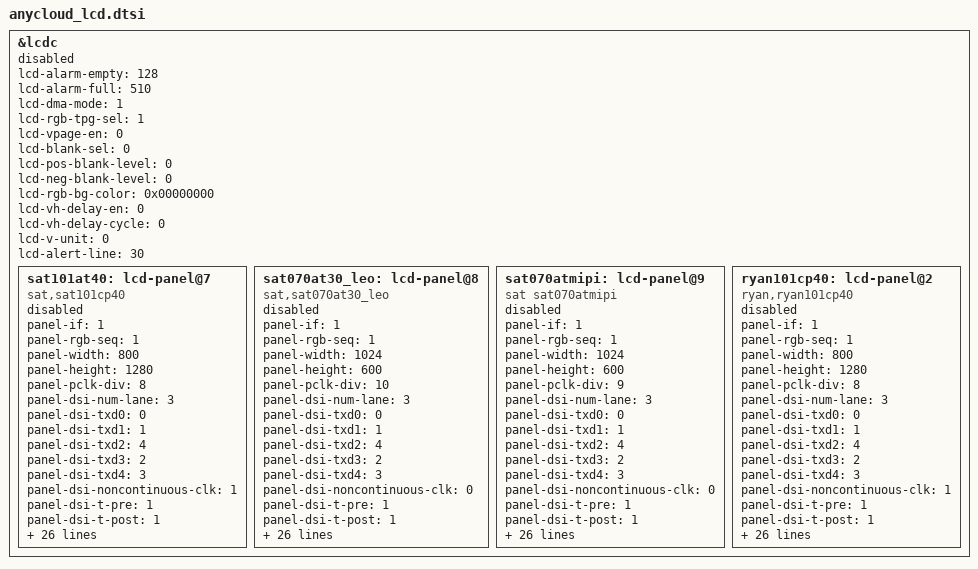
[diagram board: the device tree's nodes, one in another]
/*
 * Anycloud LCD panel dts
 *
 * Copyright (C) 2018 Anyka(Guangzhou) Microelectronics Technology Co., Ltd.
 *
 * Author: Feilong Dong <dong_feilong@anyka.com>
 *
 * This program is free software; you can redistribute it and/or modify
 * it under the terms of the GNU General Public License as published by
 * the Free Software Foundation; either version 2 of the License, or
 * (at your option) any later version.
 *
 * This program is distributed in the hope that it will be useful,
 * but WITHOUT ANY WARRANTY; without even the implied warranty of
 * MERCHANTABILITY or FITNESS FOR A PARTICULAR PURPOSE.  See the
 * GNU General Public License for more details.
 */

&lcdc {
    lcd-alarm-empty = <128>;
    lcd-alarm-full = <510>;
    lcd-dma-mode = <1>;
    //lcd-dummy-seq = <0>; //for 8bit rgb panel set
    //lcd-rgb-seq-sel = <0>;
    //lcd-rgb-odd-seq = <0>;
    //lcd-rgb-even-seq = <0>;
    lcd-rgb-tpg-sel = <1>;
    lcd-vpage-en = <0>; //don't support vpage function in driver
    lcd-blank-sel = <0>;
    lcd-pos-blank-level = <0>;
    lcd-neg-blank-level = <0>;
    lcd-rgb-bg-color = <0x00000000>;
    lcd-vh-delay-en = <0>;
    lcd-vh-delay-cycle = <0>;
    lcd-v-unit = <0>;
    lcd-alert-line = <30>;
    status = "disable";
    
    // sat070cp50: lcd-panel@0 { //for RGB panel setting
    //     compatible = "sat,sat070cp50";
    //     panel-if = <0>; //0 for RGB, 1 for MIPI, 2 for MPU
    //     panel-rgb-seq = <1>; //0 for BGR, 1 for RGB
    //     panel-width = <1024>;
    //     panel-height = <600>;
    //     panel-pclk-div = <10>; //pixel clock = Peri_pll/(pclk_div+1)
    //     panel-thpw = <60>;
    //     panel-thb = <100>;
    //     panel-thf = <120>;
    //     panel-tvpw = <2>;
    //     panel-tvb = <21>;
    //     panel-tvf = <12>;
    //     panel-pclk-pol = <0>; //0:pos, 1:neg
    //     panel-hsync-pol = <1>;
    //     panel-vsync-pol = <1>;
    //     panel-vogate-pol = <0>;
    //     panel-bus-width = <3>; //0:8bits,1:16bits,2:18bits,3:24bits
    //     panel-sync-mode = <1>; 

    //     status = "disable";
    // };

    // adt07016BR50: lcd-panel@1 { //for AJB RGB panel setting
    //     compatible = "sat,sat070cp50";
    //     panel-if = <0>; //0 for RGB, 1 for MIPI, 2 for MPU
    //     panel-rgb-seq = <1>; //0 for BGR, 1 for RGB
    //     panel-width = <1024>;
    //     panel-height = <600>;
    //     panel-pclk-div = <10>; //pixel clock = Peri_pll/(pclk_div+1)
    //     panel-thpw = <60>;
    //     panel-thb = <100>;
    //     panel-thf = <120>;
    //     panel-tvpw = <2>;
    //     panel-tvb = <21>;
    //     panel-tvf = <12>;
    //     panel-pclk-pol = <0>; //0:pos, 1:neg
    //     panel-hsync-pol = <1>;
    //     panel-vsync-pol = <1>;
    //     panel-vogate-pol = <0>;
    //     panel-bus-width = <3>; //0:8bits,1:16bits,2:18bits,3:24bits
    //     panel-sync-mode = <1>; 

    //     status = "disable";
    // };
/*

    sat101at40: lcd-panel@2 { //for JD9364 MIPI panel setting
        compatible = "sat,sat101at40";
        panel-if = <1>; //0 for RGB, 1 for MIPI, 2 for MPU
        panel-rgb-seq = <1>; //0 for BGR, 1 for RGB
        panel-width = <800>;
        panel-height = <1280>;
        panel-pclk-div = <8>; //pixel clock = Peri_pll/(pclk_div+1)
        panel-dsi-num-lane = <3>; //0-3: 1lane-4lane
        //0-3: data0-data3, 4: clk
        panel-dsi-txd0 = <2>;
        panel-dsi-txd1 = <1>;
        panel-dsi-txd2 = <4>;
        panel-dsi-txd3 = <0>;
        panel-dsi-txd4 = <3>;
        panel-dsi-noncontinuous-clk = <0>; //0:continuous,1:noncontinuous
        panel-dsi-t-pre = <1>; //t-pre, >=1
        panel-dsi-t-post = <1>; //t-post=tlpx+t-prepare+t-zero+t-pre, >=1
        panel-dsi-tx-gap = <1>; //ths-exit
        panel-dsi-autoinsert-eotp = <0>; //0:not insert,1:auto-insert
        panel-dsi-htx-to-count = <0xFFFFFF>; //high speed TX timeout count
        panel-dsi-lrx-to-count = <0xFFFFFF>; //Low power RX timeout count
        panel-dsi-bta-to-count = <0xFFFFFF>; //Bus turn around timeout count
        panel-dsi-t-wakeup = <0xc8>; //DPHY T-wakeup time
        panel-dsi-pix-fifo-send-level = <512>; //buffer send level <= 512
        //0-2:16-bit config 1-3; 3-4:18-bit config 1-2; 5:24-bit
        panel-dsi-if-color-coding = <0x05>;
        //0:16-bit;1:18-bit;2:18-bit loosely packed;3:24-bit
        panel-dsi-pix-format = <0x03>;
        panel-dsi-vsync-pol = <0>; //0:active low; 1:active high
        panel-dsi-hsync-pol = <0>; //0:active low; 1:active high
        //0:Non-burst mode with sync pulses;
        //1:Noe-burst mode with sync events;
        //2:Burst mode; 3:reserved
        panel-dsi-video-mode = <2>;
        panel-dsi-hfp = <32>; //H front porch blanking packet payload size in bytes
        panel-dsi-hbp = <8>; //H back porch blanking packet payload size in bytes
        panel-dsi-hsa = <8>; //H sync width blanking packet payload size in bytes
        panel-dsi-mult-pkts-en = <0>; //0: single packet;1: two packets
        panel-dsi-vbp = <8>; //V back porch lines
        panel-dsi-vfp = <30>; //V front porch lines
        panel-dsi-vsa = <4>;
        //0:blanking packets send during BLLP;1:LP mode used for BLLP
        panel-dsi-bllp-mode = <1>;
        panel-dsi-use-null-pkt-bllp = <0>; //0:blanking packet; 1:Null packet
        panel-dsi-vc = <0x00>; //Virtual channel
        panel-dsi-cmd-type = <0x0>; //0:send in LP mode, 1:send in HS mode
        panel-dsi-clk = <600>;
        //add special config list here
        panel-init-list = <0x00 0x23 0xE0 0x00 0xFFF
                            0x00 0x23 0xE1 0x93 0xFFF
                            0x00 0x23 0xE2 0x65 0xFFF
                            0x00 0x23 0xE3 0xF8 0xFFF
                            0x00 0x23 0x70 0x10 0xFFF
                            0x00 0x23 0x71 0x13 0xFFF
                            0x00 0x23 0x72 0x06 0xFFF
                            0x00 0x23 0x80 0x03 0xFFF
                            0x00 0x23 0xE0 0x04 0xFFF
                            0x00 0x23 0x2D 0x03 0xFFF
                            0x00 0x23 0xE0 0x01 0xFFF
                            0x00 0x23 0x00 0x00 0xFFF
                            0x00 0x23 0x01 0xB3 0xFFF
                            0x00 0x23 0x17 0x00 0xFFF
                            0x00 0x23 0x18 0xD8 0xFFF
                            0x00 0x23 0x19 0x05 0xFFF
                            0x00 0x23 0x1A 0x00 0xFFF
                            0x00 0x23 0x1B 0xD8 0xFFF
                            0x00 0x23 0x1C 0x05 0xFFF
                            0x00 0x23 0x1F 0x7E 0xFFF
                            0x00 0x23 0x20 0x28 0xFFF
                            0x00 0x23 0x21 0x28 0xFFF
                            0x00 0x23 0x22 0x0E 0xFFF
                            0x00 0x23 0x24 0xF8 0xFFF
                            0x00 0x23 0x26 0xF3 0xFFF
                            0x00 0x23 0x27 0x44 0xFFF
                            0x00 0x23 0x37 0x59 0xFFF
                            0x00 0x23 0x38 0x05 0xFFF
                            0x00 0x23 0x39 0x0C 0xFFF
                            0x00 0x23 0x3A 0x18 0xFFF
                            0x00 0x23 0x3C 0x78 0xFFF
                            0x00 0x23 0x3E 0x78 0xFFF
                            0x00 0x23 0x40 0x06 0xFFF
                            0x00 0x23 0x41 0xA0 0xFFF
                            0x00 0x23 0x55 0x01 0xFFF
                            0x00 0x23 0x56 0x01 0xFFF
                            0x00 0x23 0x57 0xA8 0xFFF
                            0x00 0x23 0x58 0x0A 0xFFF
                            0x00 0x23 0x59 0x2A 0xFFF
                            0x00 0x23 0x5A 0x3C 0xFFF
                            0x00 0x23 0x5B 0x14 0xFFF
                            0x00 0x23 0x5D 0x70 0xFFF
                            0x00 0x23 0x5E 0x53 0xFFF
                            0x00 0x23 0x5F 0x42 0xFFF
                            0x00 0x23 0x60 0x35 0xFFF
                            0x00 0x23 0x61 0x32 0xFFF
                            0x00 0x23 0x62 0x23 0xFFF
                            0x00 0x23 0x63 0x28 0xFFF
                            0x00 0x23 0x64 0x13 0xFFF
                            0x00 0x23 0x65 0x2D 0xFFF
                            0x00 0x23 0x66 0x2D 0xFFF
                            0x00 0x23 0x67 0x2D 0xFFF
                            0x00 0x23 0x68 0x4B 0xFFF
                            0x00 0x23 0x69 0x39 0xFFF
                            0x00 0x23 0x6A 0x40 0xFFF
                            0x00 0x23 0x6B 0x2F 0xFFF
                            0x00 0x23 0x6C 0x26 0xFFF
                            0x00 0x23 0x6D 0x1E 0xFFF
                            0x00 0x23 0x6E 0x07 0xFFF
                            0x00 0x23 0x6F 0x02 0xFFF
                            0x00 0x23 0x70 0x70 0xFFF
                            0x00 0x23 0x71 0x53 0xFFF
                            0x00 0x23 0x72 0x42 0xFFF
                            0x00 0x23 0x73 0x35 0xFFF
                            0x00 0x23 0x74 0x32 0xFFF
                            0x00 0x23 0x75 0x23 0xFFF
                            0x00 0x23 0x76 0x28 0xFFF
                            0x00 0x23 0x77 0x13 0xFFF
                            0x00 0x23 0x78 0x2D 0xFFF
                            0x00 0x23 0x79 0x2D 0xFFF
                            0x00 0x23 0x7A 0x2D 0xFFF
                            0x00 0x23 0x7B 0x4B 0xFFF
                            0x00 0x23 0x7C 0x39 0xFFF
                            0x00 0x23 0x7D 0x40 0xFFF
                            0x00 0x23 0x7E 0x2F 0xFFF
                            0x00 0x23 0x7F 0x26 0xFFF
                            0x00 0x23 0x80 0x1E 0xFFF
                            0x00 0x23 0x81 0x07 0xFFF
                            0x00 0x23 0x82 0x02 0xFFF
                            0x00 0x23 0xE0 0x02 0xFFF
                            0x00 0x23 0x00 0x53 0xFFF
                            0x00 0x23 0x01 0x5F 0xFFF
                            0x00 0x23 0x02 0x5F 0xFFF
                            0x00 0x23 0x03 0x5F 0xFFF
                            0x00 0x23 0x04 0x5F 0xFFF
                            0x00 0x23 0x05 0x51 0xFFF
                            0x00 0x23 0x06 0x58 0xFFF
                            0x00 0x23 0x07 0x57 0xFFF
                            0x00 0x23 0x08 0x4F 0xFFF
                            0x00 0x23 0x09 0x5F 0xFFF
                            0x00 0x23 0x0A 0x4D 0xFFF
                            0x00 0x23 0x0B 0x4B 0xFFF
                            0x00 0x23 0x0C 0x5F 0xFFF
                            0x00 0x23 0x0D 0x49 0xFFF
                            0x00 0x23 0x0E 0x47 0xFFF
                            0x00 0x23 0x0F 0x45 0xFFF
                            0x00 0x23 0x10 0x41 0xFFF
                            0x00 0x23 0x11 0x5F 0xFFF
                            0x00 0x23 0x12 0x5F 0xFFF
                            0x00 0x23 0x13 0x5F 0xFFF
                            0x00 0x23 0x14 0x5F 0xFFF
                            0x00 0x23 0x15 0x5F 0xFFF
                            0x00 0x23 0x16 0x52 0xFFF
                            0x00 0x23 0x17 0x5F 0xFFF
                            0x00 0x23 0x18 0x5F 0xFFF
                            0x00 0x23 0x19 0x5F 0xFFF
                            0x00 0x23 0x1A 0x5F 0xFFF
                            0x00 0x23 0x1B 0x50 0xFFF
                            0x00 0x23 0x1C 0x58 0xFFF
                            0x00 0x23 0x1D 0x57 0xFFF
                            0x00 0x23 0x1E 0x4E 0xFFF
                            0x00 0x23 0x1F 0x5F 0xFFF
                            0x00 0x23 0x20 0x4C 0xFFF
                            0x00 0x23 0x21 0x4A 0xFFF
                            0x00 0x23 0x22 0x5F 0xFFF
                            0x00 0x23 0x23 0x48 0xFFF
                            0x00 0x23 0x24 0x46 0xFFF
                            0x00 0x23 0x25 0x44 0xFFF
                            0x00 0x23 0x26 0x40 0xFFF
                            0x00 0x23 0x27 0x5F 0xFFF
                            0x00 0x23 0x28 0x5F 0xFFF
                            0x00 0x23 0x29 0x5F 0xFFF
                            0x00 0x23 0x2A 0x5F 0xFFF
                            0x00 0x23 0x2B 0x5F 0xFFF
                            0x00 0x23 0x2C 0x52 0xFFF
                            0x00 0x23 0x2D 0x5F 0xFFF
                            0x00 0x23 0x2E 0x5F 0xFFF
                            0x00 0x23 0x2F 0x5F 0xFFF
                            0x00 0x23 0x30 0x5F 0xFFF
                            0x00 0x23 0x31 0x40 0xFFF
                            0x00 0x23 0x32 0x58 0xFFF
                            0x00 0x23 0x33 0x57 0xFFF
                            0x00 0x23 0x34 0x44 0xFFF
                            0x00 0x23 0x35 0x5F 0xFFF
                            0x00 0x23 0x36 0x46 0xFFF
                            0x00 0x23 0x37 0x48 0xFFF
                            0x00 0x23 0x38 0x5F 0xFFF
                            0x00 0x23 0x39 0x4A 0xFFF
                            0x00 0x23 0x3A 0x4C 0xFFF
                            0x00 0x23 0x3B 0x4E 0xFFF
                            0x00 0x23 0x3C 0x50 0xFFF
                            0x00 0x23 0x3D 0x5F 0xFFF
                            0x00 0x23 0x3E 0x5F 0xFFF
                            0x00 0x23 0x3F 0x5F 0xFFF
                            0x00 0x23 0x40 0x5F 0xFFF
                            0x00 0x23 0x41 0x5F 0xFFF
                            0x00 0x23 0x42 0x53 0xFFF
                            0x00 0x23 0x43 0x5F 0xFFF
                            0x00 0x23 0x44 0x5F 0xFFF
                            0x00 0x23 0x45 0x5F 0xFFF
                            0x00 0x23 0x46 0x5F 0xFFF
                            0x00 0x23 0x47 0x41 0xFFF
                            0x00 0x23 0x48 0x58 0xFFF
                            0x00 0x23 0x49 0x57 0xFFF
                            0x00 0x23 0x4A 0x45 0xFFF
                            0x00 0x23 0x4B 0x5F 0xFFF
                            0x00 0x23 0x4C 0x47 0xFFF
                            0x00 0x23 0x4D 0x49 0xFFF
                            0x00 0x23 0x4E 0x5F 0xFFF
                            0x00 0x23 0x4F 0x4B 0xFFF
                            0x00 0x23 0x50 0x4D 0xFFF
                            0x00 0x23 0x51 0x4F 0xFFF
                            0x00 0x23 0x52 0x51 0xFFF
                            0x00 0x23 0x53 0x5F 0xFFF
                            0x00 0x23 0x54 0x5F 0xFFF
                            0x00 0x23 0x55 0x5F 0xFFF
                            0x00 0x23 0x56 0x5F 0xFFF
                            0x00 0x23 0x57 0x5F 0xFFF
                            0x00 0x23 0x58 0x10 0xFFF
                            0x00 0x23 0x59 0x00 0xFFF
                            0x00 0x23 0x5A 0x00 0xFFF
                            0x00 0x23 0x5B 0x10 0xFFF
                            0x00 0x23 0x5C 0x05 0xFFF
                            0x00 0x23 0x5D 0x30 0xFFF
                            0x00 0x23 0x5E 0x00 0xFFF
                            0x00 0x23 0x5F 0x00 0xFFF
                            0x00 0x23 0x60 0x30 0xFFF
                            0x00 0x23 0x61 0x02 0xFFF
                            0x00 0x23 0x62 0x00 0xFFF
                            0x00 0x23 0x63 0x03 0xFFF
                            0x00 0x23 0x64 0x7B 0xFFF
                            0x00 0x23 0x65 0x75 0xFFF
                            0x00 0x23 0x66 0x0B 0xFFF
                            0x00 0x23 0x67 0xB3 0xFFF
                            0x00 0x23 0x68 0x07 0xFFF
                            0x00 0x23 0x69 0x06 0xFFF
                            0x00 0x23 0x6A 0x7B 0xFFF
                            0x00 0x23 0x6B 0x04 0xFFF
                            0x00 0x23 0x6C 0x00 0xFFF
                            0x00 0x23 0x6D 0x04 0xFFF
                            0x00 0x23 0x6E 0x04 0xFFF
                            0x00 0x23 0x6F 0x88 0xFFF
                            0x00 0x23 0x70 0x00 0xFFF
                            0x00 0x23 0x71 0x00 0xFFF
                            0x00 0x23 0x72 0x06 0xFFF
                            0x00 0x23 0x73 0x7B 0xFFF
                            0x00 0x23 0x74 0x00 0xFFF
                            0x00 0x23 0x75 0x80 0xFFF
                            0x00 0x23 0x76 0x00 0xFFF
                            0x00 0x23 0x77 0x0D 0xFFF
                            0x00 0x23 0x78 0x2A 0xFFF
                            0x00 0x23 0x79 0x00 0xFFF
                            0x00 0x23 0x7A 0x00 0xFFF
                            0x00 0x23 0x7B 0x00 0xFFF
                            0x00 0x23 0x7C 0x00 0xFFF
                            0x00 0x23 0x7D 0x03 0xFFF
                            0x00 0x23 0x7E 0x7B 0xFFF
                            0x00 0x23 0xE0 0x00 0xFFF
                            0x78 0x13 0x11 0x00 0xFFF
                            0x05 0x13 0x29 0x00 0xFFF
                            0x78 0x23 0x35 0x00 0xFFF>;

        status = "disable";
    };
*/
    // ili9342c: lcd-panel@3 {
    //     compatible = "mpu,ili9342c";
    //     panel-if = <2>;//0 for RGB, 1 for MIPI, 2 for MPU
    //     panel-width = <320>;
    //     panel-height = <240>;
    //     panel-pclk-div = <1>; //default pixel clock = Peri_pll(600M)/(pclk_div+1)=60M
    //     panel-data-width = <0>; //0:8bits,1:16bits,2:18bits,3:9bits
    //     panel-color-mode = <1>; //0:4K 1:64K/256K
    //     panel-rs-polarity = <1>; //0:negative(0 means data while 1 means command)
    //                             //1:positive(0 means command while 1 means data)
    //     panel-wr-cycle = <16>; // write timing setting, wr-cycle >= 4*(wr-low) (8/9bits mode)
    //     panel-wr-low = <4>; // write timing setting,wr_cycle_len/2 - wr_low_len >= 2 (8/9bits mode)

    //     /* 0 for portrait, 1 for landscape*/
    //     panel-direction = <0>; 

    // panel-init-list = <0xC8 0xFF 0x93 0x42 0xFFF
    //                          0x36 0xC8 0xFFF
    //                          0x3A 0x55 0xFFF
    //                          0xC0 0x13 0x0E 0xFFF
    //                          0xC1 0x02 0xFFF
    //                          0xC5 0xD5 0xFFF
    //                          0xB1 0x00 0x1B 0xFFF
    //                          0xB4 0x02 0xFFF
    //                          0xE0 0x00 0x07 0x0C 0x06
    //                          0x15 0x09 0x3A 0x36 0x48
    //                          0x02 0x0B 0x0A 0x15 0x16
    //                          0x0F 0xFFF
    //                          0xE1 0x00 0x25 0x26 0x02
    //                          0x0E 0x03 0x3D 0x13 0x4E
    //                          0x03 0x0E 0x0B 0x34 0x37
    //                          0x0F 0xFFF
    //                          0x11 0xFFF
    //                          0x29 0xFFF>;
    //     status = "disable";
    // };
    

    // ili9488: lcd-panel@4 {
	// 	compatible = "mpu,ili9488";
	// 	panel-if = <2>;//0 for RGB, 1 for MIPI, 2 for MPU
	// 	panel-width = <320>;
	// 	panel-height = <480>;
	// 	panel-pclk-div = <9>; //default pixel clock = Peri_pll(600M)/(pclk_div+1)=60M
	// 	panel-data-width = <1>; //0:8bits,1:16bits,2:18bits,3:9bits
	// 	panel-color-mode = <1>; //0:4K 1:64K/256K
	// 	panel-rs-polarity = <1>; //0:negative(0 means data while 1 means command)
	// 							//1:positive(0 means command while 1 means data)
	// 	panel-wr-cycle = <8>; // write timing setting, wr-cycle >= 4*(wr-low) (8/9bits mode)
	// 	panel-wr-low = <2>; // write timing setting,wr_cycle_len/2 - wr_low_len >= 2 (8/9bits mode)

    // /* 0 for portrait, 1 for landscape*/
	// 	panel-direction = <0>;

	// 	panel-init-list = <0xE0 0x00 0x07 0x10 0x09
	// 					   0x17 0x0B 0x40 0x8A 0x4B
	// 					   0x0A 0x0D 0x0F 0x15 0x16
    //                        0x0F 0xFFF
    //                        0xE1 0x00 0x1A 0x1B 0x02
	// 					   0x0D 0x05 0x30 0x35 0x43
	// 					   0x02 0x0A 0x09 0x32 0x36
	// 					   0x0F 0xFFF
	// 					   0xB1 0xA0 0xFFF
	// 					   0xB4 0x02 0xFFF
	// 					   0xC0 0x17 0x15 0xFFF
	// 					   0xC1 0x41 0xFFF
	// 					   0xC5 0x00 0x30 0x80 0xFFF
	// 					   0xB6 0x02 0xFFF
	// 					   0x36 0x48 0xFFF
	// 					   0x3A 0x55 0xFFF
	// 					   0xE9 0x00 0xFFF
	// 					   0xF7 0xA9 0x51 0x2C 0x82 0xFFF
	// 					   0x11 0xFFF
 	// 					   0x29 0xFFF>;

 	//     status = "disable";
    // };

	// adt07029bm30: lcd-panel@5{ //for AJB 7.0 inch MIPI panel setting
    //         compatible = "adt,adt07029bm30-08";
    //         panel-if = <1>; //0 for RGB, 1 for MIPI, 2 for MPU
    //         panel-rgb-seq = <1>; //0 for BGR, 1 for RGB
    //         panel-width = <1024>;
    //         panel-height = <600>;
    //         panel-pclk-div = <8>; //pixel clock = Peri_pll/(pclk_div+1)
    //         panel-dsi-num-lane = <3>; //0-3: 1lane-4lane
    //         //0-3: data0-data3, 4: clk
    //         panel-dsi-txd0 = <0>;
    //         panel-dsi-txd1 = <1>;
    //         panel-dsi-txd2 = <4>;
    //         panel-dsi-txd3 = <2>;
    //         panel-dsi-txd4 = <3>;
    //         panel-dsi-noncontinuous-clk = <0>; //0:continuous,1:noncontinuous
    //         panel-dsi-t-pre = <1>; //t-pre, >=1
    //         panel-dsi-t-post = <1>; //t-post=tlpx+t-prepare+t-zero+t-pre, >=1
    //         panel-dsi-tx-gap = <1>; //ths-exit
    //         panel-dsi-autoinsert-eotp = <0>; //0:not insert,1:auto-insert
    //         panel-dsi-htx-to-count = <0xFFFFFF>; //high speed TX timeout count
    //         panel-dsi-lrx-to-count = <0xFFFFFF>; //Low power RX timeout count
    //         panel-dsi-bta-to-count = <0xFFFFFF>; //Bus turn around timeout count
    //         panel-dsi-t-wakeup = <0xc8>; //DPHY T-wakeup time
    //         panel-dsi-pix-fifo-send-level = <512>; //buffer send level <= 512
    //         //0-2:16-bit config 1-3; 3-4:18-bit config 1-2; 5:24-bit
    //         panel-dsi-if-color-coding = <0x05>;
    //         //0:16-bit;1:18-bit;2:18-bit loosely packed;3:24-bit
    //         panel-dsi-pix-format = <0x03>;
    //         panel-dsi-vsync-pol = <0>; //0:active low; 1:active high
    //         panel-dsi-hsync-pol = <0>; //0:active low; 1:active high
    //         //0:Non-burst mode with sync pulses;
    //         //1:Noe-burst mode with sync events;
    //         //2:Burst mode; 3:reserved
    //         panel-dsi-video-mode = <2>;
    //         panel-dsi-hfp = <40>; //H front porch blanking packet payload size in bytes
    //         panel-dsi-hbp = <20>; //H back porch blanking packet payload size in bytes
    //         panel-dsi-hsa = <20>; //H sync width blanking packet payload size in bytes
    //         panel-dsi-mult-pkts-en = <0>; //0: single packet;1: two packets
    //         panel-dsi-vbp = <8>; //V back porch lines
    //         panel-dsi-vfp = <8>; //V front porch lines
    //         panel-dsi-vsa = <4>;
    //         //0:blanking packets send during BLLP;1:LP mode used for BLLP
    //         panel-dsi-bllp-mode = <1>;
    //         panel-dsi-use-null-pkt-bllp = <0>; //0:blanking packet; 1:Null packet
    //         panel-dsi-vc = <0x00>; //Virtual channel
    //         panel-dsi-cmd-type = <0x0>; //0:send in LP mode, 1:send in HS mode
    //         panel-dsi-clk = <600>;
    //         //add special config list here
    //         panel-init-list-count = <50>;
    //         panel-init-list-line = <10>;
    //         panel-init-list =  //delay, type, data, parameters, end symbol
    //                         < 0x00 0x15 0x00 0x01 0xFFF
    //                           0x1E 0x15 0x00 0x00 0xFFF
    //                           0x00 0x15 0x8B 0x80 0xFFF
    //                           0x00 0x15 0x8B 0x80 0xFFF
    //                           0x00 0x15 0xFF 0x81 0xFFF
    //                           0x00 0x15 0x3C 0x82 0xFFF
    //                           0x00 0x15 0xFF 0x83 0xFFF
    //                           0x00 0x15 0xCA 0x84 0xFFF
    //                           0x00 0x15 0xAF 0x85 0xFFF
    //                           0x00 0x15 0xB5 0x86 0xFFF>;
    //     status = "disable";
    // };

    // sat101md40i32br1: lcd-panel@6 { //for 1920*1200 MIPI panel setting
    //         compatible = "SAT,HX8279-D";
    //         panel-if = <1>; //0 for RGB, 1 for MIPI, 2 for MPU
    //         panel-rgb-seq = <1>; //0 for BGR, 1 for RGB
    //         panel-width = <1200>;
    //         panel-height = <1920>;
    //         panel-pclk-div = <4>; //pixel clock = Peri_pll/(pclk_div+1)
    //         panel-dsi-num-lane = <3>; //0-3: 1lane-4lane
    //         //0-3: data0-data3, 4: clk
    //         panel-dsi-txd0 = <0>;
    //         panel-dsi-txd1 = <1>;
    //         panel-dsi-txd2 = <4>;
    //         panel-dsi-txd3 = <2>;
    //         panel-dsi-txd4 = <3>;
    //         panel-dsi-noncontinuous-clk = <1>; //0:continuous,1:noncontinuous
    //         panel-dsi-t-pre = <0>; //t-pre, >=1
    //         panel-dsi-t-post = <0>; //t-post=tlpx+t-prepare+t-zero+t-pre, >=1
    //         panel-dsi-tx-gap = <0>; //ths-exit
    //         panel-dsi-autoinsert-eotp = <0>; //0:not insert,1:auto-insert
    //         panel-dsi-htx-to-count = <0xFFFFFF>; //high speed TX timeout count
    //         panel-dsi-lrx-to-count = <0xFFFFFF>; //Low power RX timeout count
    //         panel-dsi-bta-to-count = <0xFFFFFF>; //Bus turn around timeout count
    //         panel-dsi-t-wakeup = <0xc8>; //DPHY T-wakeup time
    //         panel-dsi-pix-fifo-send-level = <512>; //buffer send level <= 512
    //         //0-2:16-bit config 1-3; 3-4:18-bit config 1-2; 5:24-bit
    //         panel-dsi-if-color-coding = <0x05>;
    //         //0:16-bit;1:18-bit;2:18-bit loosely packed;3:24-bit
    //         panel-dsi-pix-format = <0x03>;
    //         panel-dsi-vsync-pol = <1>; //0:active low; 1:active high
    //         panel-dsi-hsync-pol = <1>; //0:active low; 1:active high
    //         //0:Non-burst mode with sync pulses;
    //         //1:Noe-burst mode with sync events;
    //         //2:Burst mode; 3:reserved
    //         panel-dsi-video-mode = <0>;
    //         panel-dsi-hfp = <60>; //H front porch blanking packet payload size in bytes
    //         panel-dsi-hbp = <80>; //H back porch blanking packet payload size in bytes
    //         panel-dsi-hsa = <24>; //H sync width blanking packet payload size in bytes
    //         panel-dsi-mult-pkts-en = <0>; //0: single packet;1: two packets
    //         panel-dsi-vbp = <10>; //V back porch lines
    //         panel-dsi-vfp = <14>; //V front porch lines
    //         panel-dsi-vsa = <2>;
    //         //0:blanking packets send during BLLP;1:LP mode used for BLLP
    //         panel-dsi-bllp-mode = <1>;
    //         panel-dsi-use-null-pkt-bllp = <0>; //0:blanking packet; 1:Null packet
    //         panel-dsi-vc = <0x00>; //Virtual channel
    //         panel-dsi-cmd-type = <0x0>; //0:send in LP mode, 1:send in HS mode
    //         panel-dsi-clk = <820>;

    //         //add special config list here
    //         // delay, type, data, parameters, end symbol
    //         panel-init-list = < 
    //             // page1
    //             0x00 0x23 0xB0 0x01 0xFFF
    //             0x00 0x23 0xC0 0x26 0xFFF
    //             0x00 0x23 0xC1 0x10 0xFFF
    //             0x00 0x23 0xC2 0x0E 0xFFF
    //             0x00 0x23 0xC3 0x00 0xFFF
    //             0x00 0x23 0xC4 0x00 0xFFF
    //             0x00 0x23 0xC5 0x23 0xFFF
    //             0x00 0x23 0xC6 0x11 0xFFF
    //             0x00 0x23 0xC7 0x22 0xFFF
    //             0x00 0x23 0xC8 0x20 0xFFF
    //             0x00 0x23 0xC9 0x1E 0xFFF
    //             0x00 0x23 0xCA 0x1C 0xFFF
    //             0x00 0x23 0xCB 0x0C 0xFFF
    //             0x00 0x23 0xCC 0x0A 0xFFF
    //             0x00 0x23 0xCD 0x08 0xFFF
    //             0x00 0x23 0xCE 0x06 0xFFF
    //             0x00 0x23 0xCF 0x18 0xFFF
    //             0x00 0x23 0xD0 0x02 0xFFF
    //             0x00 0x23 0xD1 0x00 0xFFF
    //             0x00 0x23 0xD2 0x00 0xFFF
    //             0x00 0x23 0xD3 0x00 0xFFF
    //             0x00 0x23 0xD4 0x26 0xFFF
    //             0x00 0x23 0xD5 0x0F 0xFFF
    //             0x00 0x23 0xD6 0x0D 0xFFF
    //             0x00 0x23 0xD7 0x00 0xFFF
    //             0x00 0x23 0xD8 0x00 0xFFF
    //             0x00 0x23 0xD9 0x23 0xFFF
    //             0x00 0x23 0xDA 0x11 0xFFF
    //             0x00 0x23 0xDB 0x21 0xFFF
    //             0x00 0x23 0xDC 0x1F 0xFFF
    //             0x00 0x23 0xDD 0x1D 0xFFF
    //             0x00 0x23 0xDE 0x1B 0xFFF
    //             0x00 0x23 0xDF 0x0B 0xFFF
    //             0x00 0x23 0xE0 0x09 0xFFF
    //             0x00 0x23 0xE1 0x07 0xFFF
    //             0x00 0x23 0xE2 0x05 0xFFF
    //             0x00 0x23 0xE3 0x17 0xFFF
    //             0x00 0x23 0xE4 0x01 0xFFF
    //             0x00 0x23 0xE5 0x00 0xFFF
    //             0x00 0x23 0xE6 0x00 0xFFF
    //             0x00 0x23 0xE7 0x00 0xFFF

    //             // page3
    //             0x00 0x23 0xB0 0x03 0xFFF
    //             0x00 0x23 0xBE 0x04 0xFFF
    //             0x00 0x23 0xB9 0x40 0xFFF
    //             0x00 0x23 0xCC 0x88 0xFFF
    //             0x00 0x23 0xC8 0x0C 0xFFF
    //             0x00 0x23 0xC9 0x07 0xFFF
    //             0x00 0x23 0xCD 0x01 0xFFF
    //             0x00 0x23 0xCA 0x40 0xFFF
    //             0x00 0x23 0xCE 0x1A 0xFFF
    //             0x00 0x23 0xCF 0x60 0xFFF
    //             0x00 0x23 0xD2 0x08 0xFFF
    //             0x00 0x23 0xD3 0x08 0xFFF
    //             0x00 0x23 0xDB 0x01 0xFFF
    //             0x00 0x23 0xD9 0x06 0xFFF
    //             0x00 0x23 0xD4 0x00 0xFFF
    //             0x00 0x23 0xD5 0x01 0xFFF
    //             0x00 0x23 0xD6 0x04 0xFFF
    //             0x00 0x23 0xD7 0x03 0xFFF
    //             0x00 0x23 0xC2 0x00 0xFFF
    //             0x00 0x23 0xC3 0x0E 0xFFF
    //             0x00 0x23 0xC4 0x00 0xFFF
    //             0x00 0x23 0xC5 0x0E 0xFFF
    //             0x00 0x23 0xDD 0x00 0xFFF
    //             0x00 0x23 0xDE 0x0E 0xFFF
    //             0x00 0x23 0xE6 0x00 0xFFF
    //             0x00 0x23 0xE7 0x0E 0xFFF
    //             0x00 0x23 0xC2 0x00 0xFFF
    //             0x00 0x23 0xC3 0x0E 0xFFF
    //             0x00 0x23 0xC4 0x00 0xFFF
    //             0x00 0x23 0xC5 0x0E 0xFFF
    //             0x00 0x23 0xDD 0x00 0xFFF
    //             0x00 0x23 0xDE 0x0E 0xFFF
    //             0x00 0x23 0xE6 0x00 0xFFF
    //             0x00 0x23 0xE7 0x0E 0xFFF

    //             //  page6
    //             0x00 0x23 0xB0 0x06 0xFFF
    //             0x78 0x13 0xC0 0xA5 0xFFF
    //             0x05 0x13 0xD5 0x1C 0xFFF
    //             0x05 0x13 0xC0 0x00 0xFFF

    //             //  page0
    //             0x00 0x23 0xB0 0x00 0xFFF
    //             0x00 0x23 0xBD 0x12 0xFFF
    //             0x00 0x23 0xF9 0x5C 0xFFF
    //             0x78 0x23 0xC2 0x14 0xFFF
    //             0x05 0x23 0xC4 0x14 0xFFF
    //             0x00 0x23 0xBF 0x15 0xFFF
    //             0x00 0x23 0xC0 0x0C 0xFFF

    //             //0x00 0x23 0xB2 0x41 0xFFF // BST
    //             0x78 0x05 0x11 0x00 0xFFF   //Sleep OUT
    //             // Display ON
    //             0x0 0x05 0x29 0x00 0xFFF>;
    //         status = "disable";
    // };

    sat101at40: lcd-panel@7 {   //for JD9364 MIPI panel setting
        compatible = "sat,sat101cp40";
        panel-if = <1>;     //0 for RGB, 1 for MIPI, 2 for MPU
        panel-rgb-seq = <1>;    //0 for BGR, 1 for RGB
        panel-width = <800>;
        panel-height = <1280>;
        panel-pclk-div = <8>;   //pixel clock = Peri_pll/(pclk_div+1)
        panel-dsi-num-lane = <3>;   //0-3: 1lane-4lane
            //0-3: data0-data3, 4: clk
        panel-dsi-txd0 = <0>;
        panel-dsi-txd1 = <1>;
        panel-dsi-txd2 = <4>;
        panel-dsi-txd3 = <2>;
        panel-dsi-txd4 = <3>;
        panel-dsi-noncontinuous-clk = <1>;  //0:continuous,1:noncontinuous
        panel-dsi-t-pre = <1>;  //t-pre, >=1
        panel-dsi-t-post = <1>;     //t-post=tlpx+t-prepare+t-zero+t-pre, >=1
        panel-dsi-tx-gap = <1>;     //ths-exit
        panel-dsi-autoinsert-eotp = <0>;    //0:not insert,1:auto-insert
        panel-dsi-htx-to-count = <0xFFFFFF>;    //high speed TX timeout count
        panel-dsi-lrx-to-count = <0xFFFFFF>;    //Low power RX timeout count
        panel-dsi-bta-to-count = <0xFFFFFF>;    //Bus turn around timeout count
        panel-dsi-t-wakeup = <0xc8>;    //DPHY T-wakeup time
        panel-dsi-pix-fifo-send-level = <512>;  //buffer send level <= 512
            //0-2:16-bit config 1-3; 3-4:18-bit config 1-2; 5:24-bit
        panel-dsi-if-color-coding = <0x05>;
            //0:16-bit;1:18-bit;2:18-bit loosely packed;3:24-bit
        panel-dsi-pix-format = <0x03>;
        panel-dsi-vsync-pol = <0>;  //0:active low; 1:active high
        panel-dsi-hsync-pol = <0>;  //0:active low; 1:active high
            //0:Non-burst mode with sync pulses;
            //1:Noe-burst mode with sync events;
            //2:Burst mode; 3:reserved
        panel-dsi-video-mode = <2>;
        panel-dsi-hfp = <20>;   //H front porch blanking packet payload size in bytes
        panel-dsi-hbp = <20>;   //H back porch blanking packet payload size in bytes
        panel-dsi-hsa = <20>;   //H sync width blanking packet payload size in bytes
        panel-dsi-mult-pkts-en = <0>;   //0: single packet;1: two packets
        panel-dsi-vbp = <8>;    //V back porch lines
        panel-dsi-vfp = <30>;   //V front porch lines
        panel-dsi-vsa = <4>;
            //0:blanking packets send during BLLP;1:LP mode used for BLLP
        panel-dsi-bllp-mode = <1>;
        panel-dsi-use-null-pkt-bllp = <0>;  //0:blanking packet; 1:Null packet
        panel-dsi-vc = <0x00>;  //Virtual channel
        panel-dsi-cmd-type = <0x0>;     //0:send in LP mode, 1:send in HS mode
        panel-dsi-clk = <850>;
            //add special config list here
        panel-init-list = <0x00 0x15 0xE0 0x00 0xFFF

                            0x00 0x15 0xE1 0x93 0xFFF
                            0x00 0x15 0xE2 0x65 0xFFF
                            0x00 0x15 0xE3 0xF8 0xFFF
                            0x00 0x15 0x80 0x03 0xFFF



                            0x00 0x15 0xE0 0x01 0xFFF
                         //   0x00 0x15 0x4a 0x35 0xFFF

                            0x00 0x15 0x00 0x00 0xFFF
                            0x00 0x15 0x01 0x26 0xFFF


                            0x00 0x15 0x17 0x00 0xFFF
                            0x00 0x15 0x18 0xD7 0xFFF
                            0x00 0x15 0x19 0x01 0xFFF
                            0x00 0x15 0x1A 0x00 0xFFF
                            0x00 0x15 0x1B 0xD7 0xFFF 
                            0x00 0x15 0x1C 0x01 0xFFF

                            0x00 0x15 0x1F 0x70 0xFFF   
                            0x00 0x15 0x20 0x2D 0xFFF   
                            0x00 0x15 0x21 0x2D 0xFFF   
                            0x00 0x15 0x22 0x7E 0xFFF
                            0x00 0x15 0x24 0xFD 0xFFF

                            0x00 0x15 0x37 0x19 0xFFF   

                            0x00 0x15 0x35 0x28 0xFFF   

                            0x00 0x15 0x38 0x05 0xFFF   
                            0x00 0x15 0x39 0x08 0xFFF
                            0x00 0x15 0x3A 0x12 0xFFF
                            0x00 0x15 0x3C 0x7E 0xFFF       //SET EQ3 for TE_H
                            0x00 0x15 0x3D 0xFF 0xFFF       //SET CHGEN_ON  modify 20140806
                            0x00 0x15 0x3E 0xFF 0xFFF       //SET CHGEN_OFF  modify 20140806
                            0x00 0x15 0x3F 0x7F 0xFFF       //SET CHGEN_OFF2  modify 20140806


                            0x00 0x15 0x40 0x06 0xFFF       //RSO=
                            0x00 0x15 0x41 0xA0 0xFFF       //LN=640->1280 line
                            0x00 0x15 0x43 0x1E 0xFFF       //VFP=
                            0x00 0x15 0x44 0x0B 0xFFF       //VBP



                            0x00 0x15 0x55 0x02 0xFFF       //DCDCM=1111
                            0x00 0x15 0x56 0x01 0xFFF
                            0x00 0x15 0x57 0x6A 0xFFF
                            0x00 0x15 0x58 0x09 0xFFF
                            0x00 0x15 0x59 0x0A 0xFFF       //VCL = -2.5V
                            0x00 0x15 0x5A 0x2E 0xFFF       //VGH = 16.2V
                            0x00 0x15 0x5B 0x1A 0xFFF       //VGL = -12V
                            0x00 0x15 0x5C 0x15 0xFFF       //pump clk



                            0x00 0x15 0x5D 0x7F 0xFFF
                            0x00 0x15 0x5E 0x5D 0xFFF
                            0x00 0x15 0x5F 0x4B 0xFFF
                            0x00 0x15 0x60 0x3E 0xFFF
                            0x00 0x15 0x61 0x3A 0xFFF
                            0x00 0x15 0x62 0x2B 0xFFF
                            0x00 0x15 0x63 0x2F 0xFFF
                            0x00 0x15 0x64 0x19 0xFFF
                            0x00 0x15 0x65 0x32 0xFFF
                            0x00 0x15 0x66 0x31 0xFFF
                            0x00 0x15 0x67 0x31 0xFFF
                            0x00 0x15 0x68 0x4F 0xFFF
                            0x00 0x15 0x69 0x3E 0xFFF
                            0x00 0x15 0x6A 0x47 0xFFF
                            0x00 0x15 0x6B 0x36 0xFFF
                            0x00 0x15 0x6C 0x31 0xFFF
                            0x00 0x15 0x6D 0x24 0xFFF
                            0x00 0x15 0x6E 0x12 0xFFF
                            0x00 0x15 0x6F 0x02 0xFFF
                            0x00 0x15 0x70 0x7F 0xFFF
                            0x00 0x15 0x71 0x5D 0xFFF
                            0x00 0x15 0x72 0x4B 0xFFF
                            0x00 0x15 0x73 0x3E 0xFFF
                            0x00 0x15 0x74 0x3A 0xFFF
                            0x00 0x15 0x75 0x2B 0xFFF
                            0x00 0x15 0x76 0x2F 0xFFF
                            0x00 0x15 0x77 0x19 0xFFF
                            0x00 0x15 0x78 0x32 0xFFF
                            0x00 0x15 0x79 0x31 0xFFF
                            0x00 0x15 0x7A 0x31 0xFFF
                            0x00 0x15 0x7B 0x4F 0xFFF
                            0x00 0x15 0x7C 0x3E 0xFFF
                            0x00 0x15 0x7D 0x47 0xFFF
                            0x00 0x15 0x7E 0x36 0xFFF
                            0x00 0x15 0x7F 0x31 0xFFF
                            0x00 0x15 0x80 0x24 0xFFF
                            0x00 0x15 0x81 0x12 0xFFF
                            0x00 0x15 0x82 0x02 0xFFF

                            0x00 0x15 0xE0 0x02 0xFFF
    

                            0x00 0x15 0x00 0x52 0xFFF   //RESET_EVEN
                            0x00 0x15 0x01 0x55 0xFFF   //VSSG_EVEN
                            0x00 0x15 0x02 0x55 0xFFF   //VSSG_EVEN
                            0x00 0x15 0x03 0x50 0xFFF   //STV2_ODD
                            0x00 0x15 0x04 0x77 0xFFF   //VDD2_ODD
                            0x00 0x15 0x05 0x57 0xFFF   //VDD1_ODD
                            0x00 0x15 0x06 0x55 0xFFF   //x
                            0x00 0x15 0x07 0x4E 0xFFF   //CK11
                            0x00 0x15 0x08 0x4C 0xFFF   //CK9
                            0x00 0x15 0x09 0x5F 0xFFF   //x
                            0x00 0x15 0x0A 0x4A 0xFFF   //CK7
                            0x00 0x15 0x0B 0x48 0xFFF   //CK5
                            0x00 0x15 0x0C 0x55 0xFFF   //x
                            0x00 0x15 0x0D 0x46 0xFFF   //CK3
                            0x00 0x15 0x0E 0x44 0xFFF   //CK1
                            0x00 0x15 0x0F 0x40 0xFFF   //STV1_ODD
                            0x00 0x15 0x10 0x55 0xFFF   //x
                            0x00 0x15 0x11 0x55 0xFFF   //x
                            0x00 0x15 0x12 0x55 0xFFF   //x
                            0x00 0x15 0x13 0x55 0xFFF   //x
                            0x00 0x15 0x14 0x55 0xFFF   //x
                            0x00 0x15 0x15 0x55 0xFFF   //x

                            0x00 0x15 0x16 0x53 0xFFF   //RESET__EVEN
                            0x00 0x15 0x17 0x55 0xFFF   //VSSG_EVEN
                            0x00 0x15 0x18 0x55 0xFFF   //VSSG_EVEN
                            0x00 0x15 0x19 0x51 0xFFF   //STV2_EVEN
                            0x00 0x15 0x1A 0x77 0xFFF   //VDD2_EVEN
                            0x00 0x15 0x1B 0x57 0xFFF   //VDD1_EVEN
                            0x00 0x15 0x1C 0x55 0xFFF   //x
                            0x00 0x15 0x1D 0x4F 0xFFF   //CK12
                            0x00 0x15 0x1E 0x4D 0xFFF   //CK10
                            0x00 0x15 0x1F 0x5F 0xFFF   //x
                            0x00 0x15 0x20 0x4B 0xFFF   //CK8
                            0x00 0x15 0x21 0x49 0xFFF   //CK6
                            0x00 0x15 0x22 0x55 0xFFF   //x
                            0x00 0x15 0x23 0x47 0xFFF   //CK4
                            0x00 0x15 0x24 0x45 0xFFF   //CK2
                            0x00 0x15 0x25 0x41 0xFFF   //STV1_EVEN
                            0x00 0x15 0x26 0x55 0xFFF   //x
                            0x00 0x15 0x27 0x55 0xFFF   //x
                            0x00 0x15 0x28 0x55 0xFFF   //x
                            0x00 0x15 0x29 0x55 0xFFF   //x
                            0x00 0x15 0x2A 0x55 0xFFF   //x
                            0x00 0x15 0x2B 0x55 0xFFF   //x

                            0x00 0x15 0x2C 0x13 0xFFF   //RESET_EVEN
                            0x00 0x15 0x2D 0x15 0xFFF   //VSSG_EVEN
                            0x00 0x15 0x2E 0x15 0xFFF   //VSSG_EVEN
                            0x00 0x15 0x2F 0x01 0xFFF   //STV2_ODD
                            0x00 0x15 0x30 0x37 0xFFF   //VDD2_ODD
                            0x00 0x15 0x31 0x17 0xFFF   //VDD1_ODD
                            0x00 0x15 0x32 0x15 0xFFF   //x
                            0x00 0x15 0x33 0x0D 0xFFF   //CK11
                            0x00 0x15 0x34 0x0F 0xFFF   //CK9
                            0x00 0x15 0x35 0x15 0xFFF   //x
                            0x00 0x15 0x36 0x05 0xFFF   //CK7
                            0x00 0x15 0x37 0x07 0xFFF   //CK5
                            0x00 0x15 0x38 0x15 0xFFF   //x
                            0x00 0x15 0x39 0x09 0xFFF   //CK3
                            0x00 0x15 0x3A 0x0B 0xFFF   //CK1
                            0x00 0x15 0x3B 0x11 0xFFF   //STV1_ODD
                            0x00 0x15 0x3C 0x15 0xFFF   //x
                            0x00 0x15 0x3D 0x15 0xFFF   //x
                            0x00 0x15 0x3E 0x15 0xFFF   //x
                            0x00 0x15 0x3F 0x15 0xFFF   //x
                            0x00 0x15 0x40 0x15 0xFFF   //x
                            0x00 0x15 0x41 0x15 0xFFF   //x

                            0x00 0x15 0x42 0x12 0xFFF   //RESET__EVEN
                            0x00 0x15 0x43 0x15 0xFFF   //VSSG_EVEN
                            0x00 0x15 0x44 0x15 0xFFF   //VSSG_EVEN
                            0x00 0x15 0x45 0x00 0xFFF   //STV2_EVEN
                            0x00 0x15 0x46 0x37 0xFFF   //VDD2_EVEN
                            0x00 0x15 0x47 0x17 0xFFF   //VDD1_EVEN
                            0x00 0x15 0x48 0x15 0xFFF   //x
                            0x00 0x15 0x49 0x0C 0xFFF   //CK12
                            0x00 0x15 0x4A 0x0E 0xFFF   //CK10
                            0x00 0x15 0x4B 0x15 0xFFF   //x
                            0x00 0x15 0x4C 0x04 0xFFF   //CK8
                            0x00 0x15 0x4D 0x06 0xFFF   //CK6
                            0x00 0x15 0x4E 0x15 0xFFF   //x
                            0x00 0x15 0x4F 0x08 0xFFF   //CK4
                            0x00 0x15 0x50 0x0A 0xFFF   //CK2
                            0x00 0x15 0x51 0x10 0xFFF   //STV1_EVEN
                            0x00 0x15 0x52 0x15 0xFFF   //x
                            0x00 0x15 0x53 0x15 0xFFF   //x
                            0x00 0x15 0x54 0x15 0xFFF   //x
                            0x00 0x15 0x55 0x15 0xFFF   //x
                            0x00 0x15 0x56 0x15 0xFFF   //x
                            0x00 0x15 0x57 0x15 0xFFF   //x

                            0x00 0x15 0x58 0x40 0xFFF
                            0x00 0x15 0x5B 0x10 0xFFF
                            0x00 0x15 0x5C 0x06 0xFFF   //STV_S0
                            0x00 0x15 0x5D 0x40 0xFFF
                            0x00 0x15 0x5E 0x00 0xFFF
                            0x00 0x15 0x5F 0x00 0xFFF
                            0x00 0x15 0x60 0x40 0xFFF   //ETV_W
                            0x00 0x15 0x61 0x03 0xFFF
                            0x00 0x15 0x62 0x04 0xFFF
                            0x00 0x15 0x63 0x6C 0xFFF   //CKV_ON
                            0x00 0x15 0x64 0x6C 0xFFF   //CKV_OFF
                            0x00 0x15 0x65 0x75 0xFFF
                            0x00 0x15 0x66 0x08 0xFFF   //ETV_S0
                            0x00 0x15 0x67 0xB4 0xFFF   //ckv_num/ckv_w
                            0x00 0x15 0x68 0x08 0xFFF   //CKV_S0
                            0x00 0x15 0x69 0x6C 0xFFF   //CKV_ON
                            0x00 0x15 0x6A 0x6C 0xFFF   //CKV_OFF
                            0x00 0x15 0x6B 0x0C 0xFFF   //dummy
                            0x00 0x15 0x6D 0x00 0xFFF   //GGND1
                            0x00 0x15 0x6E 0x00 0xFFF       //GGND2
                            0x00 0x15 0x6F 0x88 0xFFF
                            0x00 0x15 0x75 0xBB 0xFFF       //FLM_EN
                            0x00 0x15 0x76 0x00 0xFFF
                            0x00 0x15 0x77 0x05 0xFFF
                            0x00 0x15 0x78 0x2A 0xFFF       //FLM_OFF

                            0x00 0x15 0xE0 0x04 0xFFF
                            0x00 0x15 0x09 0x11 0xFFF
                            0x00 0x15 0x0E 0x48 0xFFF       //Source EQ option
                            0x00 0x15 0x2D 0x03 0xFFF       //defult 0x01



                            0x00 0x15 0xE0 0x00 0xFFF
                            0x00 0x15 0xE6 0x02 0xFFF   //WD_Timer
                            0x00 0x15 0xE7 0x06 0xFFF   //WD_Timer
                            0x78 0x05 0x11 0x00 0xFFF
                            0x15 0x05 0x29 0x00 0xFFF
                            0x00 0x15 0x35 0x00 0xFFF
                            0x00 0x15 0xe0 0x00 0xFFF>;
        status = "disable";
    };
    //TN
    
     sat070at30_leo: lcd-panel@8 { //for JD9364 MIPI panel setting
        compatible = "sat,sat070at30_leo";
        panel-if = <1>; //0 for RGB, 1 for MIPI, 2 for MPU
        panel-rgb-seq = <1>; //0 for BGR, 1 for RGB
        panel-width = <1024>;
        panel-height = <600>;
        panel-pclk-div = <10>; //pixel clock = Peri_pll/(pclk_div+1)
        panel-dsi-num-lane = <3>; //0-3: 1lane-4lane
        //0-3: data0-data3, 4: clk
        panel-dsi-txd0 = <0>;
        panel-dsi-txd1 = <1>;
        panel-dsi-txd2 = <4>;
        panel-dsi-txd3 = <2>;
        panel-dsi-txd4 = <3>;
        panel-dsi-noncontinuous-clk = <0>; //0:continuous,1:noncontinuous
        panel-dsi-t-pre = <1>; //t-pre, >=1
        panel-dsi-t-post = <1>; //t-post=tlpx+t-prepare+t-zero+t-pre, >=1
        panel-dsi-tx-gap = <1>; //ths-exit
        panel-dsi-autoinsert-eotp = <0>; //0:not insert,1:auto-insert
        panel-dsi-htx-to-count = <0xFFFFFF>; //high speed TX timeout count
        panel-dsi-lrx-to-count = <0xFFFFFF>; //Low power RX timeout count
        panel-dsi-bta-to-count = <0xFFFFFF>; //Bus turn around timeout count
        panel-dsi-t-wakeup = <0xc8>; //DPHY T-wakeup time
        panel-dsi-pix-fifo-send-level = <512>; //buffer send level <= 512
        //0-2:16-bit config 1-3; 3-4:18-bit config 1-2; 5:24-bit
        panel-dsi-if-color-coding = <0x05>;
        //0:16-bit;1:18-bit;2:18-bit loosely packed;3:24-bit
        panel-dsi-pix-format = <0x03>;
        panel-dsi-vsync-pol = <0>; //0:active low; 1:active high
        panel-dsi-hsync-pol = <0>; //0:active low; 1:active high
        //0:Non-burst mode with sync pulses;
        //1:Noe-burst mode with sync events;
        //2:Burst mode; 3:reserved
        panel-dsi-video-mode = <2>;
        panel-dsi-hfp = <10>; //H front porch blanking packet payload size in bytes
        panel-dsi-hbp = <10>; //H back porch blanking packet payload size in bytes
        panel-dsi-hsa = <10>; //H sync width blanking packet payload size in bytes
        panel-dsi-mult-pkts-en = <0>; //0: single packet;1: two packets
        panel-dsi-vbp = <23>; //V back porch lines
        panel-dsi-vfp = <12>; //V front porch lines
        panel-dsi-vsa = <1>;
        //0:blanking packets send during BLLP;1:LP mode used for BLLP
        panel-dsi-bllp-mode = <1>;
        panel-dsi-use-null-pkt-bllp = <0>; //0:blanking packet; 1:Null packet
        panel-dsi-vc = <0x00>; //Virtual channel
        panel-dsi-cmd-type = <0x0>; //0:send in LP mode, 1:send in HS mode
        panel-dsi-clk = <400>;
        //add special config list here
         panel-init-list = <0x00 0x15 0x80 0xAC 0xFFF
                                0x00 0x15 0x81 0xB8 0xFFF
                                0x00 0x15 0x82 0x09 0xFFF
                                0x00 0x15 0x83 0x78 0xFFF
                                0x00 0x15 0x84 0x7F 0xFFF
                                0x00 0x15 0x85 0xB8 0xFFF
                                0x00 0x15 0x86 0x70 0xFFF
                               >;
        status = "disable";
    };



/* RGB panel*/
// &lcdc {
//     pinctrl-names = "default","sleep";
//     pinctrl-0 = <&lcd_rgb_pins &lcd_bl_pins>;
//     pinctrl-1 = <&lcd_rgb_pins_sleep>;

//     //pwr-gpio = <&gpio 82 1>;
//     //reset-pins = <&gpio 82 1>;
//     backlight-gpio = <&gpio 82 1>;

//     //lcd-logo-width = <1024>;
//     //lcd-logo-height = <600>;
//     //lcd-logo-width = <454>;
//     //lcd-logo-height = <61>;

//     lcd-logo-width = <400>;
//     lcd-logo-height = <123>;

//     //[fmt1:fmt0] 00 16bits input(RGB565 or BGR565)
//     //[fmt1:fmt0] 01 24bits input(RGB888 or BGR888)
//     //[fmt1:fmt0] 10 or 11 32bits input(ARGB888 ABGR888 RGBA888 BGRA888)

//     lcd-logo-fmt0 = <1>;
//     lcd-logo-fmt1 = <0>;
//     lcd-logo-rgb-seq = <0>; //0 for BGR, 1 for RGB

//     lcd-fb-type = <1>; //0:single buffer; 1:double buffer
//     status = "okay";
// };

//IPS
/**7寸panel **/
      sat070atmipi: lcd-panel@9 { //for JD9364 MIPI panel setting
        compatible = "sat sat070atmipi";
        panel-if = <1>; //0 for RGB  1 for MIPI  2 for MPU
        panel-rgb-seq = <1>; //0 for BGR  1 for RGB
        panel-width = <1024>;
        panel-height = <600>;
        panel-pclk-div = <9>; //pixel clock = Peri_pll/(pclk_div+1)
        panel-dsi-num-lane = <3>; //0-3: 1lane-4lane
        //0-3: data0-data3  4: clk
        panel-dsi-txd0 = <0>;
        panel-dsi-txd1 = <1>;
        panel-dsi-txd2 = <4>;
        panel-dsi-txd3 = <2>;
        panel-dsi-txd4 = <3>;
        panel-dsi-noncontinuous-clk = <0>; //0:continuous 1:noncontinuous
        panel-dsi-t-pre = <1>; //t-pre  >=1
        panel-dsi-t-post = <1>; //t-post=tlpx+t-prepare+t-zero+t-pre  >=1
        panel-dsi-tx-gap = <1>; //ths-exit
        panel-dsi-autoinsert-eotp = <0>; //0:not insert 1:auto-insert
        panel-dsi-htx-to-count = <0xFFFFFF>; //high speed TX timeout count
        panel-dsi-lrx-to-count = <0xFFFFFF>; //Low power RX timeout count
        panel-dsi-bta-to-count = <0xFFFFFF>; //Bus turn around timeout count
        panel-dsi-t-wakeup = <0xc8>; //DPHY T-wakeup time
        panel-dsi-pix-fifo-send-level = <512>; //buffer send level <= 512
        //0-2:16-bit config 1-3; 3-4:18-bit config 1-2; 5:24-bit
        panel-dsi-if-color-coding = <0x05>;
        //0:16-bit;1:18-bit;2:18-bit loosely packed;3:24-bit
        panel-dsi-pix-format = <0x03>;
        panel-dsi-vsync-pol = <0>; //0:active low; 1:active high
        panel-dsi-hsync-pol = <0>; //0:active low; 1:active high
        //0:Non-burst mode with sync pulses;
        //1:Noe-burst mode with sync events;
        //2:Burst mode; 3:reserved
        panel-dsi-video-mode = <2>;
        panel-dsi-hfp = <286>; //H front porch blanking packet payload size in bytes
        panel-dsi-hbp = <20>; //H back porch blanking packet payload size in bytes
        panel-dsi-hsa = <14>; //H sync width blanking packet payload size in bytes
        panel-dsi-mult-pkts-en = <0>; //0: single packet;1: two packets
        panel-dsi-vbp = <21>; //V back porch lines
        panel-dsi-vfp = <12>; //V front porch lines
        panel-dsi-vsa = <2>;
        //0:blanking packets send during BLLP;1:LP mode used for BLLP
        panel-dsi-bllp-mode = <1>;
        panel-dsi-use-null-pkt-bllp = <0>; //0:blanking packet; 1:Null packet
        panel-dsi-vc = <0x00>; //Virtual channel
        panel-dsi-cmd-type = <0x0>; //0:send in LP mode  1:send in HS mode
        panel-dsi-clk = <300>;
        //add special config list here
         panel-init-list = <  
            0x00 0x15 0x30 0x00 0xfff
            0x00 0x39 0xF7 0x49 0x61 0x02 0x00 0xfff
            0x00 0x15 0x30 0x01 0xfff
            0x00 0x15 0x04 0x0C 0xfff
            0x00 0x15 0x05 0x08 0xfff
            0x00 0x15 0x0B 0x10 0xfff
            0x00 0x15 0x1F 0x05 0xfff
            0x00 0x15 0x23 0x38 0xfff
            0x00 0x15 0x28 0x18 0xfff
            0x00 0x15 0x29 0x29 0xfff
            0x00 0x15 0x2A 0x01 0xfff
            0x00 0x15 0x2B 0x29 0xfff
            0x00 0x15 0x2C 0x01 0xfff
            0x00 0x15 0x30 0x02 0xfff
            0x00 0x15 0x00 0x05 0xfff
            0x00 0x15 0x01 0x22 0xfff
            0x00 0x15 0x02 0x08 0xfff
            0x00 0x15 0x03 0x12 0xfff
            0x00 0x15 0x04 0x16 0xfff
            0x00 0x15 0x05 0x64 0xfff
            0x00 0x15 0x06 0x00 0xfff
            0x00 0x15 0x07 0x00 0xfff
            0x00 0x15 0x08 0x78 0xfff
            0x00 0x15 0x09 0x00 0xfff
            0x00 0x15 0x0A 0x04 0xfff
            0x00 0x39 0x0B 0x16 0x17 0x0B 0x0D 0x0D 0x0D 0x11 0x10 0x07 0x07 0x09 0xfff
            0x00 0x39 0x0C 0x09 0x1E 0x1E 0x1C 0x1C 0x0D 0x0D 0x0D 0x0D 0x0D 0x0D 0xfff
            0x00 0x39 0x0D 0x0A 0x05 0x0B 0x0D 0x0D 0x0D 0x11 0x10 0x06 0x06 0x08 0xfff
            0x00 0x39 0x0E 0x08 0x1F 0x1F 0x1D 0x1D 0x0D 0x0D 0x0D 0x0D 0x0D 0x0D 0xfff
            0x00 0x39 0x0F 0x0A 0x05 0x0D 0x0B 0x0D 0x0D 0x11 0x10 0x1D 0x1D 0x1F 0xfff
            0x00 0x39 0x10 0x1F 0x08 0x08 0x06 0x06 0x0D 0x0D 0x0D 0x0D 0x0D 0x0D 0xfff
            0x00 0x39 0x11 0x16 0x17 0x0D 0x0B 0x0D 0x0D 0x11 0x10 0x1C 0x1C 0x1E 0xfff
            0x00 0x39 0x12 0x1E 0x09 0x09 0x07 0x07 0x0D 0x0D 0x0D 0x0D 0x0D 0x0D 0xfff
            0x00 0x39 0x13 0x00 0x00 0x00 0x00 0xfff
            0x00 0x39 0x14 0x00 0x00 0x41 0x41 0xfff
            0x00 0x39 0x15 0x00 0x00 0x00 0x00 0xfff
            0x00 0x15 0x17 0x00 0xfff
            0x00 0x15 0x18 0x85  0xfff
            0x00 0x15 0x19 0x06 0x09 0xfff
            0x00 0x15 0x1A 0x05 0x08 0xfff
            0x00 0x15 0x1B 0x0A 0x04 0xfff
            0x00 0x15 0x26 0x00 0xfff
            0x00 0x15 0x27 0x00 0xfff
            0x00 0x15 0x30 0x06 0xfff
            0x00 0x39 0x12 0x3F 0x26 0x27 0x35 0x2D 0x34 0x3F 0x3F 0x3F 0x35 0x23 0x20 0x16 0x08 0xfff
            0x00 0x39 0x13 0x3F 0x26 0x28 0x35 0x27 0x29 0x29 0x2F 0x35 0x2F 0x26 0x20 0x16 0x08 0xfff
            0x00 0x15 0x30 0x0A 0xfff
            0x00 0x15 0x02 0x4F 0xfff
            0x00 0x15 0x0B 0x40 0xfff
            0x00 0x15 0x30 0x0C 0xfff
            0x00 0x15 0x0D 0x04 0xfff
            0x00 0x15 0x10 0x0C 0xfff
            0x00 0x15 0x11 0x0C 0xfff
            0x00 0x15 0x12 0x0C 0xfff
            0x00 0x15 0x13 0x0C 0xfff
            0x00 0x15 0x30 0x00 0xfff

            0x78 0x05 0x11 0xFFF   //Sleep OUT
            0x00 0x05 0x29 0xFFF>; // Display ON
        status = "disable";
    };

/*10寸节点*/
     ryan101cp40: lcd-panel@2 { 
        compatible = "ryan,ryan101cp40";
        panel-if = <1>;     //0 for RGB, 1 for MIPI, 2 for MPU
        panel-rgb-seq = <1>;    //0 for BGR, 1 for RGB
        panel-width = <800>;
        panel-height = <1280>;
        panel-pclk-div = <8>;   //pixel clock = Peri_pll/(pclk_div+1)
        panel-dsi-num-lane = <3>;   //0-3: 1lane-4lane
                                      //0-3: data0-data3, 4: clk
        panel-dsi-txd0 = <0>;
        panel-dsi-txd1 = <1>;
        panel-dsi-txd2 = <4>;
        panel-dsi-txd3 = <2>;
        panel-dsi-txd4 = <3>;
        panel-dsi-noncontinuous-clk = <1>;  //0:continuous,1:noncontinuous
        panel-dsi-t-pre = <1>;  //t-pre, >=1
        panel-dsi-t-post = <1>;     //t-post=tlpx+t-prepare+t-zero+t-pre, >=1
        panel-dsi-tx-gap = <1>;     //ths-exit
        panel-dsi-autoinsert-eotp = <0>;    //0:not insert,1:auto-insert
        panel-dsi-htx-to-count = <0xFFFFFF>;    //high speed TX timeout count
        panel-dsi-lrx-to-count = <0xFFFFFF>;    //Low power RX timeout count
        panel-dsi-bta-to-count = <0xFFFFFF>;    //Bus turn around timeout count
        panel-dsi-t-wakeup = <0xc8>;    //DPHY T-wakeup time
        panel-dsi-pix-fifo-send-level = <512>;  //buffer send level <= 512
            //0-2:16-bit config 1-3; 3-4:18-bit config 1-2; 5:24-bit
        panel-dsi-if-color-coding = <0x05>;
            //0:16-bit;1:18-bit;2:18-bit loosely packed;3:24-bit
        panel-dsi-pix-format = <0x03>;
        panel-dsi-vsync-pol = <0>;  //0:active low; 1:active high
        panel-dsi-hsync-pol = <0>;  //0:active low; 1:active high
            //0:Non-burst mode with sync pulses;
            //1:Noe-burst mode with sync events;
            //2:Burst mode; 3:reserved
        panel-dsi-video-mode = <2>;
        panel-dsi-hfp = <40>;   //H front porch blanking packet payload size in bytes
        panel-dsi-hbp = <20>;   //H back porch blanking packet payload size in bytes
        panel-dsi-hsa = <20>;   //H sync width blanking packet payload size in bytes
        panel-dsi-mult-pkts-en = <0>;   //0: single packet;1: two packets
        panel-dsi-vbp = <20>;    //V back porch lines
        panel-dsi-vfp = <20>;   //V front porch lines
        panel-dsi-vsa = <4>;
            //0:blanking packets send during BLLP;1:LP mode used for BLLP
        panel-dsi-bllp-mode = <1>;
        panel-dsi-use-null-pkt-bllp = <0>;  //0:blanking packet; 1:Null packet
        panel-dsi-vc = <0x00>;  //Virtual channel
        panel-dsi-cmd-type = <0x0>;     //0:send in LP mode, 1:send in HS mode
        panel-dsi-clk = <850>;
            //add special config list here
        panel-init-list = <
                0X00 0X15 0xE0 0x00 0XFFF
                0X00 0X15 0xE1 0x93 0XFFF
                0X00 0X15 0xE2 0x65 0XFFF
                0X00 0X15 0xE3 0xF8 0XFFF
                0X00 0X15 0x80 0x03 0XFFF


                0X00 0X15 0xE0 0x01 0XFFF
                //0X00 0X15 0x4a 0x35 0XFFF
                0X00 0X15 0x00 0x00 0XFFF
                0X00 0X15 0x01 0x38 0XFFF
                0X00 0X15 0x03 0x10 0XFFF
                0X00 0X15 0x04 0x38 0XFFF

                0X00 0X15 0x0C 0x74 0XFFF

                0X00 0X15 0x17 0x00 0XFFF
                0X00 0X15 0x18 0xAF 0XFFF
                0X00 0X15 0x19 0x00 0XFFF
                0X00 0X15 0x1A 0x00 0XFFF
                0X00 0X15 0x1B 0xAF 0XFFF
                0X00 0X15 0x1C 0x00 0XFFF


                0X00 0X15 0x35 0x26 0XFFF

                0X00 0X15 0x37 0x09 0XFFF

                0X00 0X15 0x38 0x04 0XFFF
                0X00 0X15 0x39 0x00 0XFFF
                0X00 0X15 0x3A 0x01 0XFFF
                0X00 0X15 0x3C 0x78 0XFFF
                0X00 0X15 0x3D 0xFF 0XFFF
                0X00 0X15 0x3E 0xFF 0XFFF
                0X00 0X15 0x3F 0x7F 0XFFF

                0X00 0X15 0x40 0x06 0XFFF
                0X00 0X15 0x41 0xA0 0XFFF
                0X00 0X15 0x42 0x81 0XFFF
                0X00 0X15 0x43 0x1E 0XFFF
                0X00 0X15 0x44 0x0D 0XFFF
                0X00 0X15 0x45 0x28 0XFFF

                0X00 0X15 0x55 0x02 0XFFF
                0X00 0X15 0x57 0x69 0XFFF
                0X00 0X15 0x59 0x0A 0XFFF
                0X00 0X15 0x5A 0x2A 0XFFF
                0X00 0X15 0x5B 0x17 0XFFF

                0X00 0X15 0x5D 0x7F 0XFFF
                0X00 0X15 0x5E 0x6A 0XFFF
                0X00 0X15 0x5F 0x5B 0XFFF
                0X00 0X15 0x60 0x4F 0XFFF
                0X00 0X15 0x61 0x4A 0XFFF
                0X00 0X15 0x62 0x3D 0XFFF
                0X00 0X15 0x63 0x41 0XFFF
                0X00 0X15 0x64 0x2A 0XFFF
                0X00 0X15 0x65 0x44 0XFFF
                0X00 0X15 0x66 0x43 0XFFF
                0X00 0X15 0x67 0x44 0XFFF
                0X00 0X15 0x68 0x62 0XFFF
                0X00 0X15 0x69 0x52 0XFFF
                0X00 0X15 0x6A 0x59 0XFFF
                0X00 0X15 0x6B 0x4C 0XFFF
                0X00 0X15 0x6C 0x48 0XFFF
                0X00 0X15 0x6D 0x3A 0XFFF
                0X00 0X15 0x6E 0x26 0XFFF
                0X00 0X15 0x6F 0x00 0XFFF
                0X00 0X15 0x70 0x7F 0XFFF
                0X00 0X15 0x71 0x6A 0XFFF
                0X00 0X15 0x72 0x5B 0XFFF
                0X00 0X15 0x73 0x4F 0XFFF
                0X00 0X15 0x74 0x4A 0XFFF
                0X00 0X15 0x75 0x3D 0XFFF
                0X00 0X15 0x76 0x41 0XFFF
                0X00 0X15 0x77 0x2A 0XFFF
                0X00 0X15 0x78 0x44 0XFFF
                0X00 0X15 0x79 0x43 0XFFF
                0X00 0X15 0x7A 0x44 0XFFF
                0X00 0X15 0x7B 0x62 0XFFF
                0X00 0X15 0x7C 0x52 0XFFF
                0X00 0X15 0x7D 0x59 0XFFF
                0X00 0X15 0x7E 0x4C 0XFFF
                0X00 0X15 0x7F 0x48 0XFFF
                0X00 0X15 0x80 0x3A 0XFFF
                0X00 0X15 0x81 0x26 0XFFF
                0X00 0X15 0x82 0x00 0XFFF



                0X00 0X15 0xE0 0x02 0XFFF
                0X00 0X15 0x00 0x42 0XFFF
                0X00 0X15 0x01 0x42 0XFFF
                0X00 0X15 0x02 0x40 0XFFF
                0X00 0X15 0x03 0x40 0XFFF
                0X00 0X15 0x04 0x5E 0XFFF
                0X00 0X15 0x05 0x5E 0XFFF
                0X00 0X15 0x06 0x5F 0XFFF
                0X00 0X15 0x07 0x5F 0XFFF
                0X00 0X15 0x08 0x5F 0XFFF
                0X00 0X15 0x09 0x57 0XFFF
                0X00 0X15 0x0A 0x57 0XFFF
                0X00 0X15 0x0B 0x77 0XFFF
                0X00 0X15 0x0C 0x77 0XFFF
                0X00 0X15 0x0D 0x47 0XFFF
                0X00 0X15 0x0E 0x47 0XFFF
                0X00 0X15 0x0F 0x45 0XFFF
                0X00 0X15 0x10 0x45 0XFFF
                0X00 0X15 0x11 0x4B 0XFFF
                0X00 0X15 0x12 0x4B 0XFFF
                0X00 0X15 0x13 0x49 0XFFF
                0X00 0X15 0x14 0x49 0XFFF
                0X00 0X15 0x15 0x5F 0XFFF

                0X00 0X15 0x16 0x41 0XFFF
                0X00 0X15 0x17 0x41 0XFFF
                0X00 0X15 0x18 0x40 0XFFF
                0X00 0X15 0x19 0x40 0XFFF
                0X00 0X15 0x1A 0x5E 0XFFF
                0X00 0X15 0x1B 0x5E 0XFFF
                0X00 0X15 0x1C 0x5F 0XFFF
                0X00 0X15 0x1D 0x5F 0XFFF
                0X00 0X15 0x1E 0x5F 0XFFF
                0X00 0X15 0x1F 0x57 0XFFF
                0X00 0X15 0x20 0x57 0XFFF
                0X00 0X15 0x21 0x77 0XFFF
                0X00 0X15 0x22 0x77 0XFFF
                0X00 0X15 0x23 0x46 0XFFF
                0X00 0X15 0x24 0x46 0XFFF
                0X00 0X15 0x25 0x44 0XFFF
                0X00 0X15 0x26 0x44 0XFFF
                0X00 0X15 0x27 0x4A 0XFFF
                0X00 0X15 0x28 0x4A 0XFFF
                0X00 0X15 0x29 0x48 0XFFF
                0X00 0X15 0x2A 0x48 0XFFF
                0X00 0X15 0x2B 0x5F 0XFFF

                0X00 0X15 0x2C 0x01 0XFFF
                0X00 0X15 0x2D 0x01 0XFFF
                0X00 0X15 0x2E 0x00 0XFFF
                0X00 0X15 0x2F 0x00 0XFFF
                0X00 0X15 0x30 0x1F 0XFFF
                0X00 0X15 0x31 0x1F 0XFFF
                0X00 0X15 0x32 0x1E 0XFFF
                0X00 0X15 0x33 0x1E 0XFFF
                0X00 0X15 0x34 0x1F 0XFFF
                0X00 0X15 0x35 0x17 0XFFF
                0X00 0X15 0x36 0x17 0XFFF
                0X00 0X15 0x37 0x37 0XFFF
                0X00 0X15 0x38 0x37 0XFFF
                0X00 0X15 0x39 0x08 0XFFF
                0X00 0X15 0x3A 0x08 0XFFF
                0X00 0X15 0x3B 0x0A 0XFFF
                0X00 0X15 0x3C 0x0A 0XFFF
                0X00 0X15 0x3D 0x04 0XFFF
                0X00 0X15 0x3E 0x04 0XFFF
                0X00 0X15 0x3F 0x06 0XFFF
                0X00 0X15 0x40 0x06 0XFFF
                0X00 0X15 0x41 0x1F 0XFFF

                0X00 0X15 0x42 0x02 0XFFF
                0X00 0X15 0x43 0x02 0XFFF
                0X00 0X15 0x44 0x00 0XFFF
                0X00 0X15 0x45 0x00 0XFFF
                0X00 0X15 0x46 0x1F 0XFFF
                0X00 0X15 0x47 0x1F 0XFFF
                0X00 0X15 0x48 0x1E 0XFFF
                0X00 0X15 0x49 0x1E 0XFFF
                0X00 0X15 0x4A 0x1F 0XFFF
                0X00 0X15 0x4B 0x17 0XFFF
                0X00 0X15 0x4C 0x17 0XFFF
                0X00 0X15 0x4D 0x37 0XFFF
                0X00 0X15 0x4E 0x37 0XFFF
                0X00 0X15 0x4F 0x09 0XFFF
                0X00 0X15 0x50 0x09 0XFFF
                0X00 0X15 0x51 0x0B 0XFFF
                0X00 0X15 0x52 0x0B 0XFFF
                0X00 0X15 0x53 0x05 0XFFF
                0X00 0X15 0x54 0x05 0XFFF
                0X00 0X15 0x55 0x07 0XFFF
                0X00 0X15 0x56 0x07 0XFFF
                0X00 0X15 0x57 0x1F 0XFFF

                0X00 0X15 0x58 0x40 0XFFF
                0X00 0X15 0x5B 0x30 0XFFF
                0X00 0X15 0x5C 0x00 0XFFF
                0X00 0X15 0x5D 0x34 0XFFF
                0X00 0X15 0x5E 0x05 0XFFF
                0X00 0X15 0x5F 0x02 0XFFF
                0X00 0X15 0x63 0x00 0XFFF
                0X00 0X15 0x64 0x6A 0XFFF
                0X00 0X15 0x67 0x73 0XFFF
                0X00 0X15 0x68 0x07 0XFFF
                0X00 0X15 0x69 0x08 0XFFF
                0X00 0X15 0x6A 0x6A 0XFFF
                0X00 0X15 0x6B 0x08 0XFFF

                0X00 0X15 0x6C 0x00 0XFFF
                0X00 0X15 0x6D 0x00 0XFFF
                0X00 0X15 0x6E 0x00 0XFFF
                0X00 0X15 0x6F 0x88 0XFFF

                0X00 0X15 0x75 0xFF 0XFFF
                0X00 0X15 0x77 0xDD 0XFFF
                0X00 0X15 0x78 0x2C 0XFFF
                0X00 0X15 0x79 0x15 0XFFF
                0X00 0X15 0x7A 0x17 0XFFF
                0X00 0X15 0x7D 0x14 0XFFF
                0X00 0X15 0x7E 0x82 0XFFF

                0X00 0X15 0xE0 0x04 0XFFF
                0X00 0X15 0x00 0x0E 0XFFF
                0X00 0X15 0x02 0xB3 0XFFF
                0X00 0X15 0x09 0x61 0XFFF
                0X00 0X15 0x0E 0x48 0XFFF
                0X00 0X15 0x37 0x58 0XFFF
                0X00 0X15 0x2B 0x0F 0XFFF

                0X00 0X15 0xE0 0x00 0XFFF
                0X00 0X15 0xE6 0x02 0XFFF
                0X00 0X15 0xE7 0x0C 0XFFF
                0X78 0X05 0X11 0X00 0XFFF
                0X0A 0X05 0X29 0X00 0XFFF
                0X00 0X15 0X35 0X00 0XFFF>;
        status = "disable";
    };


//============cyy:新增屏参==============

/*SAT-7寸单IC */
    // adt07029bm30_7_IPS: lcd-panel@16{ //for AJB 7.0 inch MIPI panel setting  //IPS 单IC
    //     compatible = "adt,adt07029bm30-08_7_IPS";
    //     panel-if = <1>; //0 for RGB, 1 for MIPI, 2 for MPU
    //     panel-rgb-seq = <1>; //0 for BGR, 1 for RGB
    //     panel-width  = <1024>;
    //     panel-height = <600>;
    //     panel-pclk-div = <9>; //pixel clock = Peri_pll/(pclk_div+1)
    //     panel-dsi-num-lane = <3>; //0-3: 1lane-4lane
    //     //0-3: data0-data3, 4: clk
    //     panel-dsi-txd0 = <0>;
    //     panel-dsi-txd1 = <1>;
    //     panel-dsi-txd2 = <4>;
    //     panel-dsi-txd3 = <2>;
    //     panel-dsi-txd4 = <3>;
    //     panel-dsi-noncontinuous-clk = <0>; //0:continuous,1:noncontinuous
    //     panel-dsi-t-pre = <1>; //t-pre, >=1
    //     panel-dsi-t-post = <1>; //t-post=tlpx+t-prepare+t-zero+t-pre, >=1
    //     panel-dsi-tx-gap = <1>; //ths-exit
    //     panel-dsi-autoinsert-eotp = <0>; //0:not insert,1:auto-insert
    //     panel-dsi-htx-to-count = <0xFFFFFF>; //high speed TX timeout count
    //     panel-dsi-lrx-to-count = <0xFFFFFF>; //Low power RX timeout count
    //     panel-dsi-bta-to-count = <0xFFFFFF>; //Bus turn around timeout count
    //     panel-dsi-t-wakeup = <0xc8>; //DPHY T-wakeup time
    //     panel-dsi-pix-fifo-send-level = <512>; //buffer send level <= 512
    //     //0-2:16-bit config 1-3; 3-4:18-bit config 1-2; 5:24-bit
    //     panel-dsi-if-color-coding = <0x05>;
    //     //0:16-bit;1:18-bit;2:18-bit loosely packed;3:24-bit
    //     panel-dsi-pix-format = <0x03>;
    //     panel-dsi-vsync-pol = <0>; //0:active low; 1:active high
    //     panel-dsi-hsync-pol = <0>; //0:active low; 1:active high
    //     //0:Non-burst mode with sync pulses;
    //     //1:Noe-burst mode with sync events;
    //     //2:Burst mode; 3:reserved
    //     panel-dsi-video-mode = <1>;
    //     panel-dsi-hfp = <160>; //H front porch blanking packet payload size in bytes
    //     panel-dsi-hbp = <136>; //H back porch blanking packet payload size in bytes
    //     panel-dsi-hsa = <24>; //H sync width blanking packet payload size in bytes
    //     panel-dsi-mult-pkts-en = <0>; //0: single packet;1: two packets
    //     panel-dsi-vbp = <21>; //V back porch lines
    //     panel-dsi-vfp = <12>; //V front porch lines
    //     panel-dsi-vsa = <2>;
    //     //0:blanking packets send during BLLP;1:LP mode used for BLLP
    //     panel-dsi-bllp-mode = <1>;
    //     panel-dsi-use-null-pkt-bllp = <0>; //0:blanking packet; 1:Null packet
    //     panel-dsi-vc = <0x00>; //Virtual channel
    //     panel-dsi-cmd-type = <0x0>; //0:send in LP mode, 1:send in HS mode
    //     panel-dsi-clk = <320>;
    //     /*add special config list here */
    //     panel-init-list = <  
    //                         0x00 0x15 0x30 0x00 0xFFF
    //                         0x00 0x39 0xF7 0x49 0x61 0x02 0x00 0xFFF
    //                         0x00 0x15 0x30 0x01 0xFFF
    //                         0x00 0x15 0x04 0x0C 0xFFF
    //                         0x00 0x15 0x05 0x08 0xFFF
    //                         0x00 0x15 0x0B 0x10 0xFFF
    //                         0x00 0x15 0x1F 0x05 0xFFF
    //                         0x00 0x15 0x23 0x38 0xFFF
    //                         0x00 0x15 0x28 0x18 0xFFF
    //                         0x00 0x15 0x29 0x29 0xFFF
    //                         0x00 0x15 0x2A 0x01 0xFFF
    //                         0x00 0x15 0x2B 0x4C 0xFFF
    //                         0x00 0x15 0x2C 0x01 0xFFF
    //                         0x00 0x15 0x30 0x02 0xFFF
    //                         0x00 0x15 0x00 0x05 0xFFF
    //                         0x00 0x15 0x01 0x22 0xFFF
    //                         0x00 0x15 0x02 0x08 0xFFF
    //                         0x00 0x15 0x03 0x12 0xFFF
    //                         0x00 0x15 0x04 0x16 0xFFF
    //                         0x00 0x15 0x05 0x64 0xFFF
    //                         0x00 0x15 0x06 0x00 0xFFF
    //                         0x00 0x15 0x07 0x00 0xFFF
    //                         0x00 0x15 0x08 0x78 0xFFF
    //                         0x00 0x15 0x09 0x00 0xFFF
    //                         0x00 0x15 0x0A 0x04 0xFFF
    //                         0x00 0x39 0x0B 0x16 0x17 0x0B 0x0D 0x0D 0x0D 0x11 0x10 0x07 0x07 0x09 0xFFF
    //                         0x00 0x39 0x0C 0x09 0x1E 0x1E 0x1C 0x1C 0x0D 0x0D 0x0D 0x0D 0x0D 0x0D 0xFFF
    //                         0x00 0x39 0x0D 0x0A 0x05 0x0B 0x0D 0x0D 0x0D 0x11 0x10 0x06 0x06 0x08 0xFFF
    //                         0x00 0x39 0x0E 0x08 0x1F 0x1F 0x1D 0x1D 0x0D 0x0D 0x0D 0x0D 0x0D 0x0D 0xFFF
    //                         0x00 0x39 0x0F 0x0A 0x05 0x0D 0x0B 0x0D 0x0D 0x11 0x10 0x1D 0x1D 0x1F 0xFFF
    //                         0x00 0x39 0x10 0x1F 0x08 0x08 0x06 0x06 0x0D 0x0D 0x0D 0x0D 0x0D 0x0D 0xFFF
    //                         0x00 0x39 0x11 0x16 0x17 0x0D 0x0B 0x0D 0x0D 0x11 0x10 0x1C 0x1C 0x1E 0xFFF
    //                         0x00 0x39 0x12 0x1E 0x09 0x09 0x07 0x07 0x0D 0x0D 0x0D 0x0D 0x0D 0x0D 0xFFF
    //                         0x00 0x39 0x13 0x00 0x00 0x00 0x00 0xFFF
    //                         0x00 0x39 0x14 0x00 0x00 0x41 0x41 0xFFF
    //                         0x00 0x39 0x15 0x00 0x00 0x00 0x00 0xFFF
    //                         0x00 0x15 0x17 0x00 0xFFF
    //                         0x00 0x15 0x18 0x85 0xFFF
    //                         0x00 0x39 0x19 0x06 0x09 0xFFF
    //                         0x00 0x39 0x1A 0x05 0x08 0xFFF
    //                         0x00 0x39 0x1B 0x0A 0x04 0xFFF
    //                         0x00 0x15 0x26 0x00 0xFFF
    //                         0x00 0x15 0x27 0x00 0xFFF
    //                         0x00 0x15 0x30 0x06 0xFFF
    //                         0x00 0x39 0x12 0x3F 0x26 0x27 0x35 0x2D 0x34 0x3F 0x3F 0x3F 0x35 0x2A 0x20 0x16 0x08 0xFFF
    //                         0x00 0x39 0x13 0x3F 0x26 0x28 0x35 0x27 0x29 0x29 0x2F 0x35 0x2F 0x26 0x20 0x16 0x08 0xFFF
    //                         0x00 0x15 0x30 0x0A 0xFFF
    //                         0x00 0x15 0x02 0x4F 0xFFF
    //                         0x00 0x15 0x0B 0x40 0xFFF
    //                         0x00 0x15 0x30 0x0D 0xFFF
    //                         0x00 0x15 0x0D 0x04 0xFFF
    //                         0x00 0x15 0x10 0x0C 0xFFF
    //                         0x00 0x15 0x11 0x0C 0xFFF
    //                         0x00 0x15 0x12 0x0C 0xFFF
    //                         0x00 0x15 0x13 0x0C 0xFFF
    //                         0x00 0x15 0x30 0x00 0xFFF

    //                         0x78 0x05 0x11  0xFFF
    //                         0x14 0x05 0x29  0xFFF
    //                         >;
    //     status = "disable";
    // };
/*SAT-10.1寸 */  
    // ryan101_new: lcd-panel@10 {

    //     compatible = "ryan,ryan101_new";
    //     panel-if = <1>;                // MIPI接口
    //     panel-rgb-seq = <1>;           // RGB顺序
    //     panel-width = <800>;           // 水平分辨率
    //     panel-height = <1280>;         // 垂直分辨率

    //     panel-pclk-div = <6>;          // 时钟分频因子 
     
    //     panel-dsi-num-lane = <3>;      // 3条MIPI数据通道
    //     panel-dsi-txd0 = <0>;          // 数据通道0
    //     panel-dsi-txd1 = <1>;          // 数据通道1
    //     panel-dsi-txd2 = <4>;          // 时钟通道
    //     panel-dsi-txd3 = <2>;          // 数据通道2
    //     panel-dsi-txd4 = <3>;          // 数据通道3
    //     panel-dsi-noncontinuous-clk = <1>;

    //     panel-dsi-t-pre = <1>;
    //     panel-dsi-t-post = <1>;
    //     panel-dsi-tx-gap = <1>;
    //     panel-dsi-autoinsert-eotp = <0>;

    //     panel-dsi-htx-to-count = <0xFFFFFF>;
    //     panel-dsi-lrx-to-count = <0xFFFFFF>;
    //     panel-dsi-bta-to-count = <0xFFFFFF>;
    //     panel-dsi-t-wakeup = <0xc8>;
    //     panel-dsi-pix-fifo-send-level = <512>;

    //     panel-dsi-if-color-coding = <0x05>;  // 24-bit色彩
    //     panel-dsi-pix-format = <0x03>;       // 24-bit像素格式
    //     panel-dsi-vsync-pol = <0>;     // VSYNC低电平有效
    //     panel-dsi-hsync-pol = <0>;     // HSYNC低电平有效
        
    //     panel-dsi-video-mode = <2>;    // Non-burst模式
 
    //     panel-dsi-hfp = <20>;          // 水平前廊 
    //     panel-dsi-hbp = <20>;          // 水平后廊 
    //     panel-dsi-hsa = <20>;          // 水平同步宽度 

    //     panel-dsi-mult-pkts-en = <0>;

    //     panel-dsi-vbp = <8>;           // 垂直后廊
    //     panel-dsi-vfp = <30>;          // 垂直前廊
    //     panel-dsi-vsa = <4>;           // 垂直同步宽度
        
    //     panel-dsi-bllp-mode = <1>;
    //     panel-dsi-use-null-pkt-bllp = <0>;
    //     panel-dsi-vc = <0x00>;
    //     panel-dsi-cmd-type = <0x0>;

    //     panel-dsi-clk = <850>;         // MIPI时钟410Mbps

    //     /* 初始化序列 */
    //     panel-init-list = <
       
    //         /* 初始化命令序列 */
    //         0x00 0x15 0xE0 0x00 0xFFF

    //         0x00 0x15 0xE1 0x93 0xFFF
    //         0x00 0x15 0xE2 0x65 0xFFF
    //         0x00 0x15 0xE3 0xF8 0xFFF
    //         0x00 0x15 0x80 0x03 0xFFF

    //         0x00 0x15 0xE0 0x01 0xFFF
    //         0x00 0x15 0x00 0x00 0xFFF
    //         0x00 0x15 0x01 0x26 0xFFF

    //         0x00 0x15 0x17 0x00 0xFFF
    //         0x00 0x15 0x18 0xD7 0xFFF
    //         0x00 0x15 0x19 0x01 0xFFF
    //         0x00 0x15 0x1A 0x00 0xFFF
    //         0x00 0x15 0x1B 0xD7 0xFFF
    //         0x00 0x15 0x1C 0x01 0xFFF

    //         0x00 0x15 0x1F 0x70 0xFFF
    //         0x00 0x15 0x20 0x2D 0xFFF
    //         0x00 0x15 0x21 0x2D 0xFFF
    //         0x00 0x15 0x22 0x7E 0xFFF
    //         0x00 0x15 0x24 0xFD 0xFFF

    //         0x00 0x15 0x37 0x19 0xFFF

    //         0x00 0x15 0x35 0x28 0xFFF

    //         0x00 0x15 0x38 0x05 0xFFF
    //         0x00 0x15 0x39 0x08 0xFFF
    //         0x00 0x15 0x3A 0x12 0xFFF
    //         0x00 0x15 0x3C 0x7E 0xFFF
    //         0x00 0x15 0x3D 0xFF 0xFFF
    //         0x00 0x15 0x3E 0xFF 0xFFF
    //         0x00 0x15 0x3F 0x7F 0xFFF

    //         0x00 0x15 0x40 0x06 0xFFF
    //         0x00 0x15 0x41 0xA0 0xFFF
    //         0x00 0x15 0x43 0x1E 0xFFF
    //         0x00 0x15 0x44 0x0B 0xFFF

    //         0x00 0x15 0x55 0x02 0xFFF
    //         0x00 0x15 0x56 0x01 0xFFF
    //         0x00 0x15 0x57 0x6A 0xFFF
    //         0x00 0x15 0x58 0x09 0xFFF
    //         0x00 0x15 0x59 0x0A 0xFFF
    //         0x00 0x15 0x5A 0x2E 0xFFF
    //         0x00 0x15 0x5B 0x1A 0xFFF
    //         0x00 0x15 0x5C 0x15 0xFFF
            
    //         /* Gamma设置 (完整序列需全部包含) */
    //         0x00 0x15 0x5D 0x7F 0xFFF
    //         0x00 0x15 0x5E 0x5D 0xFFF
    //         0x00 0x15 0x5F 0x4B 0xFFF
    //         0x00 0x15 0x60 0x3E 0xFFF
    //         0x00 0x15 0x61 0x3A 0xFFF
    //         0x00 0x15 0x62 0x2B 0xFFF
    //         0x00 0x15 0x63 0x2F 0xFFF
    //         0x00 0x15 0x64 0x19 0xFFF
    //         0x00 0x15 0x65 0x32 0xFFF
    //         0x00 0x15 0x66 0x31 0xFFF
    //         0x00 0x15 0x67 0x31 0xFFF
    //         0x00 0x15 0x68 0x4F 0xFFF
    //         0x00 0x15 0x69 0x3E 0xFFF
    //         0x00 0x15 0x6A 0x47 0xFFF
    //         0x00 0x15 0x6B 0x36 0xFFF
    //         0x00 0x15 0x6C 0x31 0xFFF
    //         0x00 0x15 0x6D 0x24 0xFFF
    //         0x00 0x15 0x6E 0x12 0xFFF
    //         0x00 0x15 0x6F 0x02 0xFFF
    //         0x00 0x15 0x70 0x7F 0xFFF
    //         0x00 0x15 0x71 0x5D 0xFFF
    //         0x00 0x15 0x72 0x4B 0xFFF
    //         0x00 0x15 0x73 0x3E 0xFFF
    //         0x00 0x15 0x74 0x3A 0xFFF
    //         0x00 0x15 0x75 0x2B 0xFFF
    //         0x00 0x15 0x76 0x2F 0xFFF
    //         0x00 0x15 0x77 0x19 0xFFF
    //         0x00 0x15 0x78 0x32 0xFFF
    //         0x00 0x15 0x79 0x31 0xFFF
    //         0x00 0x15 0x7A 0x31 0xFFF
    //         0x00 0x15 0x7B 0x4F 0xFFF
    //         0x00 0x15 0x7C 0x3E 0xFFF
    //         0x00 0x15 0x7D 0x47 0xFFF
    //         0x00 0x15 0x7E 0x36 0xFFF
    //         0x00 0x15 0x7F 0x31 0xFFF
    //         0x00 0x15 0x80 0x24 0xFFF
    //         0x00 0x15 0x81 0x12 0xFFF
    //         0x00 0x15 0x82 0x02 0xFFF

            
    //         /* 更多配置 */
    //         0x00 0x15 0xE0 0x02 0xFFF
    //         0x00 0x15 0x00 0x52 0xFFF

    //         0x00 0x15 0x01 0x55 0xFFF
    //         0x00 0x15 0x02 0x55 0xFFF
    //         0x00 0x15 0x03 0x50 0xFFF
    //         0x00 0x15 0x04 0x77 0xFFF
    //         0x00 0x15 0x05 0x57 0xFFF
    //         0x00 0x15 0x06 0x55 0xFFF
    //         0x00 0x15 0x07 0x4E 0xFFF
    //         0x00 0x15 0x08 0x4C 0xFFF
    //         0x00 0x15 0x09 0x5F 0xFFF
    //         0x00 0x15 0x0A 0x4A 0xFFF
    //         0x00 0x15 0x0B 0x48 0xFFF
    //         0x00 0x15 0x0C 0x55 0xFFF
    //         0x00 0x15 0x0D 0x46 0xFFF
    //         0x00 0x15 0x0E 0x44 0xFFF
    //         0x00 0x15 0x0F 0x40 0xFFF
    //         0x00 0x15 0x10 0x55 0xFFF
    //         0x00 0x15 0x11 0x55 0xFFF
    //         0x00 0x15 0x12 0x55 0xFFF
    //         0x00 0x15 0x13 0x55 0xFFF
    //         0x00 0x15 0x14 0x55 0xFFF
    //         0x00 0x15 0x15 0x55 0xFFF
            
    //         0x00 0x15 0x16 0x53 0xFFF
    //         0x00 0x15 0x17 0x55 0xFFF
    //         0x00 0x15 0x18 0x55 0xFFF
    //         0x00 0x15 0x19 0x51 0xFFF
    //         0x00 0x15 0x1A 0x77 0xFFF
    //         0x00 0x15 0x1B 0x57 0xFFF
    //         0x00 0x15 0x1C 0x55 0xFFF
    //         0x00 0x15 0x1D 0x4F 0xFFF
    //         0x00 0x15 0x1E 0x4D 0xFFF
    //         0x00 0x15 0x1F 0x5F 0xFFF
    //         0x00 0x15 0x20 0x4B 0xFFF
    //         0x00 0x15 0x21 0x49 0xFFF
    //         0x00 0x15 0x22 0x55 0xFFF
    //         0x00 0x15 0x23 0x47 0xFFF
    //         0x00 0x15 0x24 0x45 0xFFF
    //         0x00 0x15 0x25 0x41 0xFFF
    //         0x00 0x15 0x26 0x55 0xFFF
    //         0x00 0x15 0x27 0x55 0xFFF
    //         0x00 0x15 0x28 0x55 0xFFF
    //         0x00 0x15 0x29 0x55 0xFFF
    //         0x00 0x15 0x2A 0x55 0xFFF
    //         0x00 0x15 0x2B 0x55 0xFFF
            
    //         0x00 0x15 0x2C 0x13 0xFFF
    //         0x00 0x15 0x2D 0x15 0xFFF
    //         0x00 0x15 0x2E 0x15 0xFFF
    //         0x00 0x15 0x2F 0x01 0xFFF
    //         0x00 0x15 0x30 0x37 0xFFF
    //         0x00 0x15 0x31 0x17 0xFFF
    //         0x00 0x15 0x32 0x15 0xFFF
    //         0x00 0x15 0x33 0x0D 0xFFF
    //         0x00 0x15 0x34 0x0F 0xFFF
    //         0x00 0x15 0x35 0x15 0xFFF
    //         0x00 0x15 0x36 0x05 0xFFF
    //         0x00 0x15 0x37 0x07 0xFFF
    //         0x00 0x15 0x38 0x15 0xFFF
    //         0x00 0x15 0x39 0x09 0xFFF
    //         0x00 0x15 0x3A 0x0B 0xFFF
    //         0x00 0x15 0x3B 0x11 0xFFF
    //         0x00 0x15 0x3C 0x15 0xFFF
    //         0x00 0x15 0x3D 0x15 0xFFF
    //         0x00 0x15 0x3E 0x15 0xFFF
    //         0x00 0x15 0x3F 0x15 0xFFF
    //         0x00 0x15 0x40 0x15 0xFFF
    //         0x00 0x15 0x41 0x15 0xFFF
            
    //         0x00 0x15 0x42 0x12 0xFFF
    //         0x00 0x15 0x43 0x15 0xFFF
    //         0x00 0x15 0x44 0x15 0xFFF
    //         0x00 0x15 0x45 0x00 0xFFF
    //         0x00 0x15 0x46 0x37 0xFFF
    //         0x00 0x15 0x47 0x17 0xFFF
    //         0x00 0x15 0x48 0x15 0xFFF
    //         0x00 0x15 0x49 0x0C 0xFFF
    //         0x00 0x15 0x4A 0x0E 0xFFF
    //         0x00 0x15 0x4B 0x15 0xFFF
    //         0x00 0x15 0x4C 0x04 0xFFF
    //         0x00 0x15 0x4D 0x06 0xFFF
    //         0x00 0x15 0x4E 0x15 0xFFF
    //         0x00 0x15 0x4F 0x08 0xFFF
    //         0x00 0x15 0x50 0x0A 0xFFF
    //         0x00 0x15 0x51 0x10 0xFFF
    //         0x00 0x15 0x52 0x15 0xFFF
    //         0x00 0x15 0x53 0x15 0xFFF
    //         0x00 0x15 0x54 0x15 0xFFF
    //         0x00 0x15 0x55 0x15 0xFFF
    //         0x00 0x15 0x56 0x15 0xFFF
    //         0x00 0x15 0x57 0x15 0xFFF
           
    //         0x00 0x15 0x58 0x40 0xFFF
    //         0x00 0x15 0x5B 0x10 0xFFF
    //         0x00 0x15 0x5C 0x06 0xFFF
    //         0x00 0x15 0x5D 0x40 0xFFF
    //         0x00 0x15 0x5E 0x00 0xFFF
    //         0x00 0x15 0x5F 0x00 0xFFF
    //         0x00 0x15 0x60 0x40 0xFFF
    //         0x00 0x15 0x61 0x03 0xFFF
    //         0x00 0x15 0x62 0x04 0xFFF
    //         0x00 0x15 0x63 0x6C 0xFFF
    //         0x00 0x15 0x64 0x6C 0xFFF
    //         0x00 0x15 0x65 0x75 0xFFF
    //         0x00 0x15 0x66 0x08 0xFFF
    //         0x00 0x15 0x67 0xB4 0xFFF
    //         0x00 0x15 0x68 0x08 0xFFF
    //         0x00 0x15 0x69 0x6C 0xFFF
    //         0x00 0x15 0x6A 0x6C 0xFFF
    //         0x00 0x15 0x6B 0x0C 0xFFF
    //         0x00 0x15 0x6D 0x00 0xFFF
    //         0x00 0x15 0x6E 0x00 0xFFF
    //         0x00 0x15 0x6F 0x88 0xFFF
    //         0x00 0x15 0x75 0xBB 0xFFF
    //         0x00 0x15 0x76 0x00 0xFFF
    //         0x00 0x15 0x77 0x05 0xFFF
    //         0x00 0x15 0x78 0x2A 0xFFF
           
    //         /* 最后阶段 */ 
    //         0x00 0x15 0xE0 0x04 0xFFF
    //         0x00 0x15 0x09 0x11 0xFFF
    //         0x00 0x15 0x0E 0x48 0xFFF
    //         0x00 0x15 0x2D 0x03 0xFFF
    //         0x00 0x15 0xE0 0x00 0xFFF
    //         0x00 0x15 0xE6 0x02 0xFFF
    //         0x00 0x15 0xE7 0x06 0xFFF
            
    //         /* 退出睡眠 */
    //         0x78 0x05 0x11 0x00 0xFFF   
    //         0x00 0x05 0x29 0x00 0xFFF

    //         0x00 0x15 0x35 0x00 0xFFF
    //         0x00 0x15 0xE0 0x00 0xFFF   /* 立即发送 0xE0 0x00*/
    //         >;
    //     status = "disable";
    // };



};
